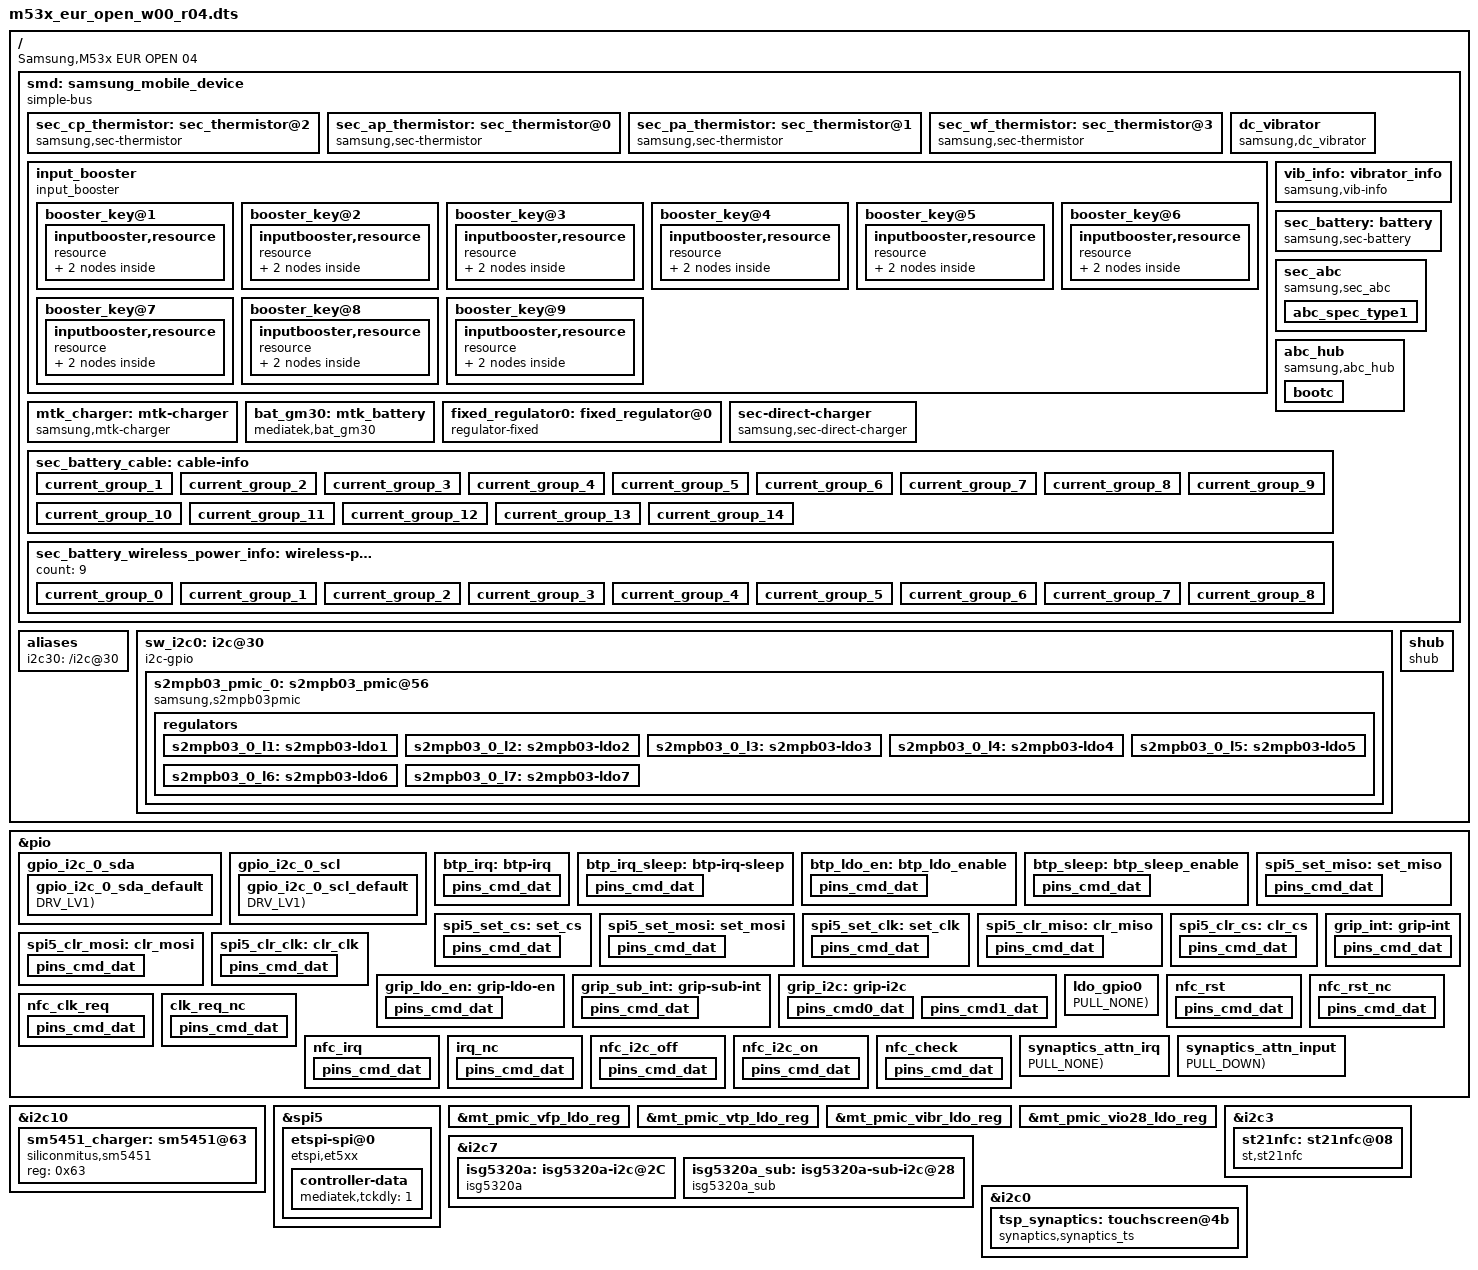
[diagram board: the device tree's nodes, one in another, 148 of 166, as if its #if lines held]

/*
 * Copyright (c) 2018 Samsung Electronics Co., Ltd.
 *              http://www.samsung.com
 *
 * This program is free software; you can redistribute it and/or modify
 * it under the terms of the GNU General Public License version 2 as
 * published by the Free Software Foundation.
*/

/dts-v1/;
/plugin/;
/ {
	fragment@smd {
		target-path = "/";
		__overlay__ {
			smd: samsung_mobile_device {
				compatible = "simple-bus";
			};
		};
	};
};

/* #include "../common/input_booster_mt6877.dtsi" */ /* From input_booster_mt6877.py */
/* Copyright (c) 2019, The Linux Foundation. All rights reserved.
 *
 * This program is free software; you can redistribute it and/or modify
 * it under the terms of the GNU General Public License version 2 and
 * only version 2 as published by the Free Software Foundation.
 *
 * This program is distributed in the hope that it will be useful,
 * but WITHOUT ANY WARRANTY; without even the implied warranty of
 * MERCHANTABILITY or FITNESS FOR A PARTICULAR PURPOSE.  See the
 * GNU General Public License for more details.
 */

&smd {
	input_booster {
		status = "okay";
		compatible = "input_booster";
		resValcount = "2";
		max_resource_count = "3";
		max_cluster_count = "3";
		#address-cells = <1>;
		#size-cells = <0>;

		/* Each Cpu Cluster Start Cpu */
		cpu_cluster_policy = "6,0";

		/* < CPU, DDR, SCHEDBOOST > */
		ib_release_values = "-1,16,0";

		/* Select Allowed Resource Index Group */
		allowed_resources = "0,1";

		booster_key@1 {
			input_booster,label = "key";
			input_booster,type = <0>;	/* BOOSTER_DEVICE_KEY */

			/* Time table */
			input_booster,head_time = <200>;
			input_booster,tail_time = <0>;

			/* Resource Table Sequentially identified with index
			 * CPU's ID & Index : 0
			 * DDR's ID & Index : 1
			*/

			/* Input Booster Resource Frequency */
			inputbooster,resource {
				compatible = "resource";
				resource@1 {
					resource,label = "CPU";
					resource,value = <1540000 0>;
				};

				resource@2 {
					resource,label = "DDR";
					resource,value = <0 0>;
				};
			};
		};

		booster_key@2 {
			input_booster,label = "touchkey";
			input_booster,type = <1>;	/* BOOSTER_DEVICE_TOUCHKEY */

			/* Time table */
			input_booster,head_time = <1>;
			input_booster,tail_time = <300>;

			/* Input Booster Resource Frequency */
			inputbooster,resource {
				compatible = "resource";
				resource@1 {
					resource,label = "CPU";
					resource,value = <0 1540000>;
				};

				resource@2 {
					resource,label = "DDR";
					resource,value = <0 0>;
				};
			};
		};

		booster_key@3 {
			input_booster,label = "touch";
			input_booster,type = <2>;	/* BOOSTER_DEVICE_TOUCH */

			/* Time table */
			input_booster,head_time = <130>;
			input_booster,tail_time = <500>;

			/* Input Booster Resource Frequency */
			inputbooster,resource {
				compatible = "resource";
				resource@1 {
					resource,label = "CPU";
					resource,value = <1140000 1075200>;
				};

				resource@2 {
					resource,label = "DDR";
					resource,value = <4266 4266>;
				};
			};
		};

		booster_key@4 {
			input_booster,label = "multitouch";
			input_booster,type = <3>;	/* BOOSTER_DEVICE_MULTITOUCH */

			/* Time table */
			input_booster,head_time = <1000>;
			input_booster,tail_time = <500>;

			/* Input Booster Resource Frequency */
			inputbooster,resource {
				compatible = "resource";
				resource@1 {
					resource,label = "CPU";
					resource,value = <1140000 1075200>;
				};

				resource@2 {
					resource,label = "DDR";
					resource,value = <4266 4266>;
				};
			};
		};

		booster_key@5 {
			input_booster,label = "keyboard";
			input_booster,type = <4>;	/* BOOSTER_DEVICE_KEYBOARD */

			/* Time table */
			input_booster,head_time = <130>;
			input_booster,tail_time = <130>;

			/* Input Booster Resource Frequency */
			inputbooster,resource {
				compatible = "resource";
				resource@1 {
					resource,label = "CPU";
					resource,value = <1430000 1040000>;
				};

				resource@2 {
					resource,label = "DDR";
					resource,value = <4266 4266>;
				};
			};
		};

		booster_key@6 {
			input_booster,label = "MOUSE";
			input_booster,type = <5>;	/* BOOSTER_DEVICE_MOUSE */

			/* Time table */
			input_booster,head_time = <200>;
			input_booster,tail_time = <300>;

			/* Input Booster Resource Frequency */
			inputbooster,resource {
				compatible = "resource";
				resource@1 {
					resource,label = "CPU";
					resource,value = <1430000 1040000>;
				};

				resource@2 {
					resource,label = "DDR";
					resource,value = <4266 4266>;
				};
			};
		};

		booster_key@7 {
			input_booster,label = "mouse_wheel";
			input_booster,type = <6>;	/* BOOSTER_DEVICE_MOUSE */

			/* Time table */
			input_booster,head_time = <200>;
			input_booster,tail_time = <0>;

			/* Input Booster Resource Frequency */
			inputbooster,resource {
				compatible = "resource";
				resource@1 {
					resource,label = "CPU";
					resource,value = <1430000 0>;
				};

				resource@2 {
					resource,label = "DDR";
					resource,value = <4266 0>;
				};
			};
		};

		booster_key@8 {
			input_booster,label = "pen_hover";
			input_booster,type = <7>;	/* BOOSTER_DEVICE_MOUSE */

			/* Time table */
			input_booster,head_time = <200>;
			input_booster,tail_time = <300>;

			/* Input Booster Resource Frequency */
			inputbooster,resource {
				compatible = "resource";
				resource@1 {
					resource,label = "CPU";
					resource,value = <1430000 1040000>;
				};

				resource@2 {
					resource,label = "DDR";
					resource,value = <0 0>;
				};
			};
		};

		booster_key@9 {
			input_booster,label = "pen";
			input_booster,type = <8>;	/* BOOSTER_DEVICE_MOUSE */

			/* Time table */
			input_booster,head_time = <200>;
			input_booster,tail_time = <600>;

			/* Input Booster Resource Frequency */
			inputbooster,resource {
				compatible = "resource";
				resource@1 {
					resource,label = "CPU";
					resource,value = <1800000 1040000>;
				};

				resource@2 {
					resource,label = "DDR";
					resource,value = <4266 4266>;
				};
			};
		};
		/* If you need to add new key type, add it this position */
	};
};

/* #include "../sec_pinctrl_wrapper.dtsi" */         /* From sec_pinctrl_wrapper.py */
#define PIN_FUNC_INPUT		input-enable
#define PIN_FUNC_INPUT_WAKEUP	input-enable
#define PIN_FUNC_OUTPUT		output-enable
#define PIN_FUNC_OUTPUT_HIGH		output-high
#define PIN_FUNC_OUTPUT_LOW		output-low

#define PIN_PULL_NONE	bias-disable
#define PIN_PULL_DOWN	bias-pull-down
#define PIN_PULL_UP	bias-pull-up
#define PIN_PULL_OPEN	bias-high-impedance

/*
 * MTK_DRIVE_2mA  2
 * MTK_DRIVE_4mA  4
 * MTK_DRIVE_6mA  6
 * MTK_DRIVE_8mA  8
 * MTK_DRIVE_10mA 10
 * MTK_DRIVE_12mA 12
 * MTK_DRIVE_14mA 14
 * MTK_DRIVE_16mA 16
 */

#define PIN_DRV_LV1	2
#define PIN_DRV_LV2	4
#define PIN_DRV_LV3	6
#define PIN_DRV_LV4	8
#define PIN_DRV_LV5	10
#define PIN_DRV_LV6	12
#define PIN_DRV_LV7	14
#define PIN_DRV_LV8	16

#define PIN_EXPAND(pin) #pin

#define SEC_GPIO(src, type, num)	PIN_EXPAND(gpio##num)
#define SEC_GPIO_REF(src, type, num)	&type num
#define SEC_GPIO_NUM(src, type, num)	num
#define SEC_GPIO_TYPE(src, type, num)	&type
#define SEC_GPIO_PHANDLE_ACTIVE(src, type, num)	SEC_GPIO_PHANDLE(type, num, active)
#define SEC_GPIO_PHANDLE_SLEEP(src, type, num)	SEC_GPIO_PHANDLE(type, num, sleep)
#define SEC_GPIO_PHANDLE(type, num, mode)	type##_##num##_##mode

#define MTK_PINMUX(gpio, func) (MTK_PIN_NO(gpio) | func)

#define GPIO_CONFIG(_src, _type, _num, _func)		\
	pins_cmd_dat{					\
		pinmux = <MTK_PINMUX(SEC_GPIO_NUM(_src, _type, _num), 0)>;	\
		PIN_ ##_func;		\
	}

#define GPIO_CONFIG_PUD(_src, _type, _num, _func, _pull)	\
	pins_cmd_dat{					\
		pinmux = <MTK_PINMUX(SEC_GPIO_NUM(_src, _type, _num), 0)>;	\
		PIN_ ##_pull;				\
		PIN_ ##_func;		\
	}

#define GPIO_CONFIG_PUD_DRV(_src, _type, _num, _func, _pull, _drv)	\
	pins_cmd_dat{					\
		pinmux = <MTK_PINMUX(SEC_GPIO_NUM(_src, _type, _num), 0)>;	\
		PIN_ ##_pull;				\
		PIN_ ##_func;		\
		drive-strength = <PIN_ ##_drv>;	\
	}

#define SEC_ADC(type, num) <&type num>
#define SEC_ADC_OPT(type, num) ,<&type num>
#define SEC_ADC_NUM(type, num) <num>

/* #include "../vibrator_vib_info.dtsi" */           /* From vibrator_vib_info.py */

&smd {
	vib_info: vibrator_info {
		status = "okay";
		compatible = "samsung,vib-info";
		functions = "";
#if 0
		samsung,intensities = <>;
#else
		samsung,intensities = <>;
#endif

#if 0
		samsung,haptic_intensities = <>;
#else
		samsung,haptic_intensities = <>;
#endif
	};
};

/* #include "../mtk_charger.dtsi" */                 /* From mtk_charger.py */

&smd {
	mtk_charger: mtk-charger {
		compatible = "samsung,mtk-charger";
#if defined(CONFIG_SEC_FACTORY)
		charger,vbus_min_charger_voltage = <4200000>;
		charger,vbus_normal_mivr_voltage = <4200000>;
#else
		charger,vbus_min_charger_voltage = <4400000>;
		charger,vbus_normal_mivr_voltage = <4400000>;
#endif
		charger,gpio_ilim = <&pio 140 0x0>;
		charger,gpio_chgenb = <&pio 135 0x0>;
		charger,max_icl = <3250>;
		charger,ib_fcc = <100>;
	};

	battery {
		battery,otg_name = "mtk-otg";
	};
};

/* /home/dpi/qb5_8814/workspace/P4_1716/android/kernel/kmodule/battery/suwon/charger/mtk_charger/mtk_charger.m53x.dtsi */

&smd {
	mtk_charger: mtk-charger {
		charger,vbus_min_charger_voltage = <4400000>;
		charger,vbus_normal_mivr_voltage = <4400000>;
		charger,gpio_ilim = <&pio 111 0x0>;
		charger,gpio_chgenb = <&pio 142 0x0>;
	};
};

/* #include "../mtk_fuelgauge.dtsi" */               /* From mtk_fuelgauge.py */
&smd {
	battery {
		battery,fuelgauge_name = "mtk-fg-battery";
	};

	/* battery_prop.dtsi */
	bat_gm30: mtk_battery{
		compatible = "mediatek,bat_gm30";
		DIFFERENCE_FULLOCV_ITH = <(300)>;
	/*	Charging termination current*/
		SHUTDOWN_1_TIME = <(60)>;
	/*	If ui_soc shows 1% more than X minites, system will shutdown*/
		KEEP_100_PERCENT = <(1)>;
	/*	The ui_soc will keep 100% until SOC drop X percents after unplugged */
		R_FG_VALUE = <(5)>;
	/*	R_sense resistance*/
		EMBEDDED_SEL = <(0)>;
	/*	Configures whether using embedded battery or not*/
		PMIC_SHUTDOWN_CURRENT = <(20)>;
	/*	System shutdown current*/
		FG_METER_RESISTANCE = <(100)>;
	/*	The resistance of PCB*/
		CAR_TUNE_VALUE = <(99)>;
	/*	Tune value for current measurement*/
		PMIC_MIN_VOL = <(33500)>;
	/*	vboot voltage for gauge 0%*/
		POWERON_SYSTEM_IBOOT = <(500)>;
	/*	power on system iboot*/
		SHUTDOWN_GAUGE0 = <(0)>;
	/*	Shutdown condition2 switch*/
		SHUTDOWN_GAUGE0_VOLTAGE = <(34000)>;
	/*	shutdown gauge 0% voltage*/
		TEMPERATURE_T0 = <(50)>;
	/*	Battery temperature T0*/
		TEMPERATURE_T1 = <(25)>;
	/*	Battery temperature T1*/
		TEMPERATURE_T2 = <(10)>;
	/*	Battery temperature T2*/
		TEMPERATURE_T3 = <(0)>;
	/*	Battery temperature T3*/
		TEMPERATURE_T4 = <(-10)>;
	/*	Battery temperature T4*/
		TEMPERATURE_T5 = <(-20)>;
	/*	Battery temperature T5*/
		g_FG_PSEUDO100_T0 = <(93)>;
	/*	Pseudo 100% percentage at T0*/
		g_FG_PSEUDO100_T1 = <(93)>;
	/*	Pseudo 100% percentage at T1*/
		g_FG_PSEUDO100_T2 = <(93)>;
	/*	Pseudo 100% percentage at T2*/
		g_FG_PSEUDO100_T3 = <(93)>;
	/*	Pseudo 100% percentage at T3*/
		g_FG_PSEUDO100_T4 = <(93)>;
	/*	Pseudo 100% percentage at T4*/
		g_FG_PSEUDO100_T5 = <(93)>;
	/*	Pseudo 100% percentage at T4*/
		Q_MAX_SYS_VOLTAGE_BAT0 = <(3350)>;
	/*	Pseudo1 for hide percentage*/
		Q_MAX_SYS_VOLTAGE_BAT1 = <(3350)>;
	/*	Pseudo1 for hide percentage*/
		Q_MAX_SYS_VOLTAGE_BAT2 = <(3350)>;
	/*	Pseudo1 for hide percentage*/
		Q_MAX_SYS_VOLTAGE_BAT3 = <(3350)>;
	/*	Pseudo1 for hide percentage*/
		COM_FG_METER_RESISTANCE = <(100)>;
	/*	compensate The resistance of PCB*/
		COM_R_FG_VALUE = <(0)>;
	/*	compensate R_sense resistance*/
		enable_tmp_intr_suspend = <(0)>;
	/* Enable update temp when suspend */
		ACTIVE_TABLE = <(6)>;
	/* Table numbers per battery*/
		MULTI_TEMP_GAUGE0 = <(1)>;
	/* Multi gauge0 enable*/
		HWOCV_OLDOCV_DIFF = <(100)>;
	/* Diff of HWOCV and SWOCV*/

	/* battery_table.dtsi*/
	battery0_profile_t0_num = <100>;
	battery0_profile_t0_col = <3>;
	battery0_profile_t0 =
	<
	0       43520   850
	486     43380   866
	972     43251   875
	1458    43130   897
	1944    43004   875
	2430    42881   875
	2916    42760   875
	3402    42644   875
	3888    42530   900
	4375    42407   875
	4861    42293   881
	5347    42178   900
	5833    42054   875
	6319    41941   897
	6805    41820   875
	7291    41714   875
	7777    41601   900
	8263    41485   875
	8749    41372   875
	9235    41267   897
	9721    41155   875
	10207   41051   875
	10693   40945   875
	11179   40837   884
	11665   40739   875
	12152   40642   900
	12638   40542   894
	13124   40446   919
	13610   40350   900
	14096   40253   900
	14582   40162   919
	15068   40070   925
	15554   39979   925
	16040   39898   941
	16526   39817   950
	17012   39736   950
	17498   39655   962
	17984   39573   975
	18470   39492   975
	18956   39411   1000
	19442   39329   1025
	19928   39210   975
	20415   39078   938
	20901   38949   878
	21387   38849   875
	21873   38773   850
	22359   38699   850
	22845   38635   850
	23331   38580   850
	23817   38521   850
	24303   38472   850
	24789   38423   850
	25275   38374   875
	25761   38326   850
	26247   38285   869
	26733   38239   850
	27219   38200   875
	27705   38157   866
	28192   38115   868
	28678   38082   872
	29164   38050   875
	29650   38007   853
	30136   37975   875
	30622   37952   900
	31108   37919   900
	31594   37887   900
	32080   37865   907
	32566   37841   925
	33052   37810   925
	33538   37765   900
	34024   37684   861
	34510   37614   865
	34996   37550   851
	35482   37511   859
	35968   37465   857
	36455   37424   853
	36941   37374   850
	37427   37337   875
	37913   37304   875
	38399   37272   875
	38885   37230   875
	39371   37185   900
	39857   37120   875
	40343   37063   875
	40829   37004   888
	41315   36942   879
	41801   36861   881
	42287   36806   860
	42773   36790   875
	43259   36780   891
	43745   36767   907
	44232   36751   948
	44718   36719   976
	45204   36643   1018
	45690   36372   937
	46176   35944   969
	46662   35387   1000
	47148   34581   1041
	47634   33318   1181
	48120   30130   10325
	>;
	battery0_profile_t1_num = <100>;
	battery0_profile_t1_col = <3>;
	battery0_profile_t1 =
	<
	0       43320   1450
	486     43164   1450
	972     43033   1475
	1458    42911   1475
	1944    42789   1475
	2430    42671   1475
	2916    42550   1456
	3402    42434   1475
	3888    42320   1475
	4375    42197   1440
	4861    42083   1431
	5347    41968   1428
	5833    41854   1437
	6319    41741   1428
	6805    41628   1431
	7291    41514   1425
	7777    41401   1425
	8263    41295   1425
	8749    41184   1407
	9235    41078   1403
	9721    40975   1412
	10207   40871   1425
	10693   40765   1425
	11179   40667   1416
	11665   40569   1425
	12152   40475   1450
	12638   40382   1450
	13124   40277   1450
	13610   40190   1450
	14096   40093   1447
	14582   40002   1444
	15068   39920   1460
	15554   39839   1450
	16040   39758   1450
	16526   39687   1500
	17012   39606   1500
	17498   39525   1500
	17984   39443   1504
	18470   39354   1525
	18956   39243   1490
	19442   39109   1425
	19928   38980   1344
	20415   38875   1319
	20901   38787   1300
	21387   38719   1313
	21873   38654   1300
	22359   38589   1300
	22845   38535   1290
	23331   38480   1300
	23817   38431   1291
	24303   38384   1300
	24789   38343   1300
	25275   38294   1300
	25761   38257   1303
	26247   38217   1325
	26733   38182   1309
	27219   38140   1325
	27705   38107   1341
	28192   38075   1332
	28678   38042   1350
	29164   38010   1350
	29650   37987   1375
	30136   37955   1375
	30622   37926   1375
	31108   37900   1376
	31594   37877   1384
	32080   37855   1400
	32566   37822   1378
	33052   37790   1375
	33538   37747   1375
	34024   37707   1356
	34510   37672   1360
	34996   37630   1351
	35482   37591   1359
	35968   37552   1350
	36455   37512   1372
	36941   37480   1375
	37427   37447   1375
	37913   37414   1394
	38399   37368   1385
	38885   37310   1376
	39371   37248   1393
	39857   37192   1400
	40343   37134   1423
	40829   37063   1412
	41315   36975   1425
	41801   36935   1425
	42287   36920   1460
	42773   36910   1475
	43259   36894   1500
	43745   36867   1514
	44232   36833   1573
	44718   36727   1613
	45204   36421   1607
	45690   35937   1688
	46176   35299   1804
	46662   34415   1951
	47148   32710   2488
	47634   30570   11550
	48120   30570   11550
	>;
	battery0_profile_t2_num = <100>;
	battery0_profile_t2_col = <3>;
	battery0_profile_t2 =
	<
	0       43000   3200
	486     42808   3293
	972     42661   3412
	1458    42531   3472
	1944    42404   3476
	2430    42281   3478
	2916    42160   3481
	3402    42044   3484
	3888    41930   3475
	4375    41817   3485
	4861    41695   3456
	5347    41579   3431
	5833    41474   3450
	6319    41361   3425
	6805    41255   3425
	7291    41144   3425
	7777    41041   3425
	8263    40931   3416
	8749    40834   3407
	9235    40737   3425
	9721    40640   3425
	10207   40541   3444
	10693   40435   3419
	11179   40337   3425
	11665   40229   3375
	12152   40138   3391
	12638   40047   3381
	13124   39957   3378
	13610   39875   3400
	14096   39794   3375
	14582   39712   3375
	15068   39640   3415
	15554   39559   3425
	16040   39472   3409
	16526   39382   3425
	17012   39269   3381
	17498   39146   3350
	17984   39008   3268
	18470   38894   3225
	18956   38801   3200
	19442   38720   3200
	19928   38655   3200
	20415   38590   3200
	20901   38534   3222
	21387   38479   3225
	21873   38426   3250
	22359   38377   3250
	22845   38329   3275
	23331   38280   3275
	23817   38241   3300
	24303   38202   3325
	24789   38162   3347
	25275   38130   3363
	25761   38087   3378
	26247   38055   3400
	26733   38022   3425
	27219   37990   3425
	27705   37967   3466
	28192   37935   3500
	28678   37911   3500
	29164   37885   3525
	29650   37859   3528
	30136   37842   3569
	30622   37822   3600
	31108   37800   3601
	31594   37784   3641
	32080   37757   3657
	32566   37732   3697
	33052   37700   3700
	33538   37667   3728
	34024   37627   3750
	34510   37592   3795
	34996   37559   3850
	35482   37517   3866
	35968   37482   3932
	36455   37434   3972
	36941   37374   4026
	37427   37314   4104
	37913   37249   4144
	38399   37190   4235
	38885   37119   4325
	39371   37028   4398
	39857   36965   4501
	40343   36932   4666
	40829   36905   4816
	41315   36877   5048
	41801   36845   5310
	42287   36790   5653
	42773   36689   6028
	43259   36466   6433
	43745   36033   6914
	44232   35419   7720
	44718   34544   8974
	45204   33115   11297
	45690   30950   12525
	46176   30950   12525
	46662   30950   12525
	47148   30950   12525
	47634   30950   12525
	48120   30950   12525
	>;
	battery0_profile_t3_num = <100>;
	battery0_profile_t3_col = <3>;
	battery0_profile_t3 =
	<
	0       42520   5950
	486     42262   6183
	972     42098   6518
	1458    41961   6640
	1944    41824   6714
	2430    41701   6753
	2916    41580   6775
	3402    41464   6816
	3888    41350   6825
	4375    41237   6840
	4861    41123   6825
	5347    41017   6847
	5833    40909   6825
	6319    40812   6847
	6805    40715   6844
	7291    40604   6825
	7777    40501   6825
	8263    40385   6784
	8749    40274   6782
	9235    40177   6800
	9721    40080   6800
	10207   39984   6778
	10693   39903   6781
	11179   39821   6784
	11665   39739   6800
	12152   39658   6791
	12638   39587   6825
	13124   39497   6803
	13610   39410   6813
	14096   39312   6797
	14582   39196   6756
	15068   39069   6680
	15554   38949   6625
	16040   38836   6584
	16526   38747   6569
	17012   38666   6550
	17498   38600   6575
	17984   38536   6579
	18470   38479   6600
	18956   38418   6635
	19442   38370   6675
	19928   38321   6691
	20415   38275   6706
	20901   38234   6725
	21387   38194   6750
	21873   38156   6775
	22359   38115   6794
	22845   38082   6835
	23331   38050   6850
	23817   38018   6891
	24303   37984   6907
	24789   37952   6925
	25275   37930   6975
	25761   37909   7003
	26247   37892   7044
	26733   37876   7084
	27219   37860   7125
	27705   37843   7183
	28192   37827   7214
	28678   37811   7295
	29164   37795   7351
	29650   37777   7407
	30136   37752   7488
	30622   37722   7544
	31108   37689   7626
	31594   37657   7723
	32080   37622   7813
	32566   37582   7939
	33052   37540   8076
	33538   37495   8238
	34024   37437   8422
	34510   37374   8610
	34996   37309   8853
	35482   37238   9080
	35968   37170   9352
	36455   37096   9676
	36941   37004   10017
	37427   36935   10393
	37913   36894   10858
	38399   36862   11389
	38885   36830   11982
	39371   36791   12670
	39857   36740   13453
	40343   36656   14301
	40829   36424   15025
	41315   35986   15823
	41801   35349   16953
	42287   34442   18475
	42773   33430   18575
	43259   33430   18575
	43745   33430   18575
	44232   33430   18575
	44718   33430   18575
	45204   33430   18575
	45690   33430   18575
	46176   33430   18575
	46662   33430   18575
	47148   33430   18575
	47634   33430   18575
	48120   33430   18575
	>;
	battery0_profile_t4_num = <100>;
	battery0_profile_t4_col = <3>;
	battery0_profile_t4 =
	<
	0       42010   11330
	486     41738   11604
	972     41429   12066
	1458    41171   12469
	1944    40989   12751
	2430    40838   12878
	2916    40700   12919
	3402    40570   12916
	3888    40440   12875
	4375    40311   12819
	4861    40181   12744
	5347    40058   12703
	5833    39949   12675
	6319    39842   12650
	6805    39745   12650
	7291    39648   12616
	7777    39541   12526
	8263    39441   12509
	8749    39332   12437
	9235    39227   12378
	9721    39115   12312
	10207   39013   12272
	10693   38923   12250
	11179   38841   12216
	11665   38759   12200
	12152   38694   12184
	12638   38622   12175
	13124   38565   12175
	13610   38510   12200
	14096   38456   12178
	14582   38407   12200
	15068   38358   12210
	15554   38310   12225
	16040   38261   12241
	16526   38215   12256
	17012   38174   12297
	17498   38140   12325
	17984   38097   12329
	18470   38065   12350
	18956   38032   12375
	19442   38010   12450
	19928   37977   12475
	20415   37955   12506
	20901   37931   12568
	21387   37905   12626
	21873   37874   12675
	22359   37855   12770
	22845   37832   12819
	23331   37800   12900
	23817   37778   13031
	24303   37744   13121
	24789   37712   13242
	25275   37670   13327
	25761   37626   13460
	26247   37577   13639
	26733   37535   13728
	27219   37480   13875
	27705   37420   14031
	28192   37359   14202
	28678   37294   14386
	29164   37230   14552
	29650   37155   14720
	30136   37090   14944
	30622   37028   15148
	31108   36979   15354
	31594   36947   15613
	32080   36905   15847
	32566   36863   16130
	33052   36790   16376
	33538   36673   16644
	34024   36429   16891
	34510   36018   17215
	34996   35399   17761
	35482   34431   18699
	35968   32802   17069
	36455   31080   12750
	36941   31080   12750
	37427   31080   12750
	37913   31080   12750
	38399   31080   12750
	38885   31080   12750
	39371   31080   12750
	39857   31080   12750
	40343   31080   12750
	40829   31080   12750
	41315   31080   12750
	41801   31080   12750
	42287   31080   12750
	42773   31080   12750
	43259   31080   12750
	43745   31080   12750
	44232   31080   12750
	44718   31080   12750
	45204   31080   12750
	45690   31080   12750
	46176   31080   12750
	46662   31080   12750
	47148   31080   12750
	47634   31080   12750
	48120   31080   12750
	>;
	battery0_profile_t5_num = <100>;
	battery0_profile_t5_col = <3>;
	battery0_profile_t5 =
	<
	0       40920   10780
	483     40610   11233
	967     40337   12231
	1450    40095   12975
	1933    39872   13686
	2417    39674   14479
	2900    39510   15208
	3383    39378   15667
	3867    39258   15931
	4350    39150   16075
	4833    39042   16178
	5317    38929   16164
	5800    38830   16208
	6283    38733   16319
	6767    38652   16378
	7250    38573   16404
	7733    38509   16464
	8217    38444   16519
	8700    38390   16625
	9183    38335   16666
	9667    38292   16706
	10150   38244   16725
	10633   38200   16750
	11117   38158   16752
	11600   38126   16810
	12083   38087   16833
	12567   38052   16965
	13050   38019   16990
	13533   37987   17100
	14017   37955   17176
	14500   37919   17218
	14983   37880   17323
	15467   37838   17390
	15950   37794   17510
	16433   37738   17550
	16917   37683   17714
	17400   37629   17828
	17883   37564   17981
	18367   37500   18070
	18850   37427   18222
	19333   37361   18385
	19817   37286   18407
	20300   37222   18563
	20783   37158   18764
	21267   37093   18919
	21750   37039   19080
	22233   36974   19247
	22717   36910   19451
	23200   36824   19655
	23683   36692   19921
	24167   36470   20134
	24650   36118   20420
	25133   35546   20803
	25617   34662   21167
	26100   33270   18200
	26583   32530   16450
	27067   32530   16450
	27550   32530   16450
	28033   32530   16450
	28517   32530   16450
	29000   32530   16450
	29483   32530   16450
	29967   32530   16450
	30450   32530   16450
	30933   32530   16450
	31417   32530   16450
	31900   32530   16450
	32383   32530   16450
	32867   32530   16450
	33350   32530   16450
	33833   32530   16450
	34317   32530   16450
	34800   32530   16450
	35283   32530   16450
	35767   32530   16450
	36250   32530   16450
	36733   32530   16450
	37217   32530   16450
	37700   32530   16450
	38183   32530   16450
	38667   32530   16450
	39150   32530   16450
	39633   32530   16450
	40117   32530   16450
	40600   32530   16450
	41083   32530   16450
	41567   32530   16450
	42050   32530   16450
	42533   32530   16450
	43017   32530   16450
	43500   32530   16450
	43983   32530   16450
	44467   32530   16450
	44950   32530   16450
	45433   32530   16450
	45917   32530   16450
	46400   32530   16450
	46883   32530   16450
	47367   32530   16450
	47850   32530   16450
	>;

	/* battery_prop_dim2_ext.dtsi */
	/*vboot voltage for gauge 0%*/
	g_PMIC_MIN_VOL_row = <4>;
	g_PMIC_MIN_VOL_col = <10>;
	g_PMIC_MIN_VOL =
	<
		32700  32700  32700  32700
		32700  32700  32700  32700
		32700  32700  32700  32700
		32200  32200  32200  32200
		31000  31000  31000  31000
		31500  31500  31500  31500
		31000  31000  31000  31000
		31000  31000  31000  31000
		31000  31000  31000  31000
		31000  31000  31000  31200
	>;
	/*boot_up current for gauge 0%*/
	g_PON_SYS_IBOOT_row = <4>;
	g_PON_SYS_IBOOT_col = <10>;
	g_PON_SYS_IBOOT =
	<
		5000  5000  5000  5000
		5000  5000  5000  5000
		5000  5000  5000  5000
		5000  5000  5000  5000
		5000  5000  5000  5000
		5000  5000  5000  5000
		5000  5000  5000  5000
		5000  5000  5000  5000
		5000  5000  5000  5000
		5000  5000  5000  5000
	>;
	/*Pseudo1 hide percentage*/
	g_QMAX_SYS_VOL_row = <4>;
	g_QMAX_SYS_VOL_col = <10>;
	g_QMAX_SYS_VOL =
	<
		33600  33600  33600  33600
		33600  33600  33600  33600
		33600  33600  33600  33600
		33600  33600  33600  33600
		33600  33600  33600  33600
		32500  32500  32500  32500
		32800  32800  32800  32800
		32800  32800  32800  32800
		32800  32800  32800  32800
		32800  32800  32800  32800
	>;
	/*Pseudo100 percentage setting*/
	g_FG_PSEUDO100_row = <4>;
	g_FG_PSEUDO100_col = <10>;
	g_FG_PSEUDO100 =
	<
		91  100  100  100
		91  100  100  100
		91  100  100  100
		91  100  100  100
		91  100  100  100
		91  100  100  100
		100  100  100  100
		100  100  100  100
		100  100  100  100
		100  100  100  100
	>;

	};
};

/* /home/dpi/qb5_8814/workspace/P4_1716/android/kernel/kmodule/battery/suwon/fuelgauge/mtk_fuelgauge/mtk_fuelgauge.m53x.dtsi */
&smd {
	battery {
		battery,fuelgauge_name = "mtk-fg-battery";
	};

	/* battery_prop.dtsi */
bat_gm30: mtk_battery{
	compatible = "mediatek,bat_gm30";

	RBAT_TYPE = <(100)>;
	RBAT_PULL_UP_R = <(100000)>;

	rbat_temperature_table_num = <21>;
	rbat_battery_temperature =
	<
		(-40) 4397119
		(-35) 3088598
		(-30) 2197225
		(-25) 1581880
		(-20) 1151036
		(-15) 846578
		(-10) 628988
		(-5) 471632
		0 357011
		5 272499
		10 209709
		15 162650
		20 127080
		25 100000
		30 79221
		35 63167
		40 50676
		45 40903
		50 33194
		55 27090
		60 22224 >;
/* battery temperature table type - NTC table */
	BatteryID_GPIO_1 = <&pio 21 0>;
	BatteryID_GPIO = <&pio 22 0>;
/* Battery ID distinction */
	DIFFERENCE_FULLOCV_ITH = <(300)>; /* M53 : 250mA +50mA */
/*	Charging termination current*/
	SHUTDOWN_1_TIME = <(60)>;
/*	If ui_soc shows 1% more than X minites, system will shutdown*/
	KEEP_100_PERCENT = <(1)>;
/*	The ui_soc will keep 100% until SOC drop X percents after unplugged*/
	R_FG_VALUE = <(5)>;
/*	R_sense resistance*/
	EMBEDDED_SEL = <(0)>;
/*	Configures whether using embedded battery or not*/
	PMIC_SHUTDOWN_CURRENT = <(20)>;
/*	System shutdown current*/
	FG_METER_RESISTANCE = <(100)>;
/*	The resistance of PCB*/
	CAR_TUNE_VALUE = <(100)>;
/*	Tune value for current measurement*/
	PMIC_MIN_VOL = <(33500)>;
/*	vboot voltage for gauge 0%*/
	POWERON_SYSTEM_IBOOT = <(500)>;
/*	power on system iboot*/
	SHUTDOWN_GAUGE0 = <(0)>;
/*	Shutdown condition2 switch*/
	SHUTDOWN_GAUGE0_VOLTAGE = <(34000)>;
/*	shutdown gauge 0% voltage*/
	TEMPERATURE_T0 = <(50)>;
/*	Battery temperature T0*/
	TEMPERATURE_T1 = <(25)>;
/*	Battery temperature T1*/
	TEMPERATURE_T2 = <(10)>;
/*	Battery temperature T2*/
	TEMPERATURE_T3 = <(0)>;
/*	Battery temperature T3*/
	TEMPERATURE_T4 = <(-10)>;
/*	Battery temperature T4*/
	TEMPERATURE_T5 = <(-20)>;
/*	Battery temperature T5*/
	g_FG_PSEUDO100_T0 = <(100)>;
/*	Pseudo 100% percentage at T0*/
	g_FG_PSEUDO100_T1 = <(100)>;
/*	Pseudo 100% percentage at T1*/
	g_FG_PSEUDO100_T2 = <(100)>;
/*	Pseudo 100% percentage at T2*/
	g_FG_PSEUDO100_T3 = <(100)>;
/*	Pseudo 100% percentage at T3*/
	g_FG_PSEUDO100_T4 = <(100)>;
/*	Pseudo 100% percentage at T4*/
	g_FG_PSEUDO100_T5 = <(100)>;
/*	Pseudo 100% percentage at T4*/
	Q_MAX_SYS_VOLTAGE_BAT0 = <(3350)>;
/*	Pseudo1 for hide percentage*/
	Q_MAX_SYS_VOLTAGE_BAT1 = <(3350)>;
/*	Pseudo1 for hide percentage*/
	Q_MAX_SYS_VOLTAGE_BAT2 = <(3350)>;
/*	Pseudo1 for hide percentage*/
	Q_MAX_SYS_VOLTAGE_BAT3 = <(3350)>;
/*	Pseudo1 for hide percentage*/
	COM_FG_METER_RESISTANCE = <(100)>;
/*	compensate The resistance of PCB*/
	COM_R_FG_VALUE = <(0)>;
/*	compensate R_sense resistance*/
	enable_tmp_intr_suspend = <(0)>;
/* Enable update temp when suspend */
	ACTIVE_TABLE = <(6)>;
/* Table numbers per battery*/
	MULTI_TEMP_GAUGE0 = <(1)>;
/* Multi gauge0 enable*/
	HWOCV_OLDOCV_DIFF = <(100)>;
/* Diff of HWOCV and SWOCV*/
	UI_FULL_LIMIT_EN = <(1)>;
	UI_FULL_LIMIT_SOC0 = <(9545)>;
	UI_FULL_LIMIT_ITH0 = <(14000)>;
	UI_FULL_LIMIT_SOC1 = <(9645)>;
	UI_FULL_LIMIT_ITH1 = <(12500)>;
	UI_FULL_LIMIT_SOC2 = <(9745)>;
	UI_FULL_LIMIT_ITH2 = <(11000)>;
	UI_FULL_LIMIT_SOC3 = <(9845)>;
	UI_FULL_LIMIT_ITH3 = <(9500)>;
	UI_FULL_LIMIT_SOC4 = <(9945)>;
	UI_FULL_LIMIT_ITH4 = <(7700)>;
/* Using current to limit uisoc in 100% case*/
	DYNAMIC_CV_FACTOR = <(100)>;
/* Dynamic CV offset */
	CHARGER_IEOC = <(250)>;
/* Charger termination current for Dynamic CV */

/* battery_table.dtsi*/
battery0_profile_t0_num = <100>;
battery0_profile_t0_col = <3>;
battery0_profile_t0 =
<
0       43990   475
474     43854   475
948     43739   500
1423    43628   500
1897    43515   500
2371    43404   500
2845    43289   488
3320    43182   500
3794    43062   500
4268    42949   500
4742    42831   500
5217    42708   498
5691    42587   501
6165    42471   510
6639    42354   525
7114    42228   506
7588    42111   516
8062    41992   524
8536    41876   525
9011    41751   503
9485    41640   525
9959    41529   532
10433   41419   550
10908   41298   525
11382   41185   525
11856   41081   541
12330   40974   550
12805   40863   530
13279   40762   565
13753   40652   526
14227   40551   550
14702   40450   550
15176   40355   569
15650   40260   575
16124   40165   575
16598   40070   575
17073   39985   600
17547   39897   616
18021   39806   607
18495   39719   625
18970   39628   625
19444   39529   625
19918   39397   585
20392   39246   525
20867   39127   506
21341   39032   509
21815   38952   501
22289   38879   500
22764   38816   500
23238   38752   500
23712   38689   500
24186   38633   500
24661   38576   500
25135   38519   500
25609   38471   500
26083   38424   525
26558   38376   525
27032   38329   525
27506   38280   525
27980   38239   514
28455   38197   525
28929   38158   525
29403   38121   525
29877   38082   547
30352   38051   550
30826   38018   552
31300   37980   558
31774   37945   550
32248   37913   550
32723   37874   555
33197   37810   500
33671   37731   514
34145   37654   505
34620   37599   506
35094   37550   500
35568   37511   523
36042   37455   500
36517   37417   525
36991   37369   508
37465   37334   525
37939   37294   503
38414   37257   525
38888   37199   524
39362   37136   500
39836   37074   505
40311   37018   505
40785   36951   510
41259   36872   525
41733   36825   489
42208   36819   522
42682   36803   500
43156   36797   525
43630   36772   525
44105   36746   550
44579   36662   550
45053   36398   566
45527   36003   625
46002   35496   665
46476   34819   735
46950   33830   850
>;
battery0_profile_t1_num = <100>;
battery0_profile_t1_col = <3>;
battery0_profile_t1 =
<
0       43900   750
474     43774   750
948     43669   800
1423    43558   781
1897    43449   784
2371    43344   800
2845    43234   800
3320    43122   800
3794    43002   800
4268    42889   800
4742    42771   800
5217    42648   800
5691    42527   801
6165    42411   810
6639    42286   800
7114    42168   800
7588    42051   800
8062    41932   800
8536    41811   800
9011    41701   803
9485    41583   807
9959    41469   807
10433   41359   825
10908   41248   825
11382   41135   825
11856   41031   841
12330   40924   850
12805   40813   850
13279   40712   850
13753   40611   874
14227   40511   875
14702   40410   879
15176   40307   881
15650   40210   883
16124   40115   900
16598   40030   925
17073   39935   925
17547   39847   925
18021   39754   925
18495   39667   946
18970   39564   925
19444   39459   924
19918   39317   845
20392   39186   796
20867   39075   775
21341   38982   741
21815   38912   749
22289   38839   738
22764   38776   750
23238   38712   733
23712   38659   743
24186   38603   747
24661   38546   725
25135   38499   750
25609   38451   750
26083   38404   750
26558   38356   750
27032   38319   750
27506   38270   750
27980   38233   750
28455   38196   771
28929   38155   750
29403   38124   775
29877   38092   797
30352   38061   787
30826   38028   798
31300   37997   792
31774   37965   800
32248   37933   779
32723   37902   800
33197   37860   775
33671   37817   761
34145   37766   750
34620   37727   750
35094   37690   750
35568   37642   727
36042   37595   725
36517   37558   727
36991   37519   733
37465   37484   750
37939   37453   750
38414   37407   750
38888   37349   750
39362   37286   750
39836   37234   755
40311   37178   775
40785   37101   750
41259   37022   774
41733   36975   764
42208   36960   775
42682   36953   775
43156   36937   782
43630   36921   822
44105   36886   825
44579   36822   873
45053   36575   866
45527   36160   911
46002   35630   990
46476   34925   1123
46950   33930   1425
>;
battery0_profile_t2_num = <100>;
battery0_profile_t2_col = <3>;
battery0_profile_t2 =
<
0       43620   1525
474     43458   1554
948     43337   1625
1423    43218   1644
1897    43095   1659
2371    42975   1675
2845    42859   1675
3320    42742   1675
3794    42622   1692
4268    42499   1675
4742    42381   1696
5217    42259   1686
5691    42137   1675
6165    42017   1675
6639    41904   1695
7114    41785   1675
7588    41671   1691
8062    41554   1699
8536    41442   1700
9011    41331   1725
9485    41220   1707
9959    41109   1725
10433   40999   1725
10908   40892   1725
11382   40788   1726
11856   40685   1750
12330   40584   1775
12805   40481   1775
13279   40376   1785
13753   40281   1800
14227   40177   1800
14702   40082   1800
15176   39985   1819
15650   39890   1825
16124   39786   1802
16598   39685   1813
17073   39563   1771
17547   39421   1709
18021   39290   1644
18495   39170   1604
18970   39074   1589
19444   38989   1550
19918   38920   1560
20392   38851   1571
20867   38780   1550
21341   38720   1559
21815   38662   1551
22289   38609   1575
22764   38557   1578
23238   38502   1583
23712   38452   1575
24186   38404   1596
24661   38356   1600
25135   38319   1625
25609   38271   1609
26083   38234   1625
26558   38186   1625
27032   38153   1650
27506   38121   1650
27980   38079   1650
28455   38047   1675
28929   38015   1675
29403   37984   1675
29877   37952   1697
30352   37921   1700
30826   37889   1676
31300   37857   1700
31774   37825   1700
32248   37793   1700
32723   37752   1685
33197   37710   1675
33671   37673   1700
34145   37627   1704
34620   37595   1725
35094   37554   1725
35568   37522   1747
36042   37476   1787
36517   37418   1800
36991   37353   1817
37465   37292   1831
37939   37245   1871
38414   37174   1885
38888   37090   1900
39362   37023   1925
39836   36998   1958
40311   36983   2018
40785   36957   2041
41259   36941   2097
41733   36916   2162
42208   36866   2256
42682   36714   2366
43156   36354   2472
43630   35840   2650
44105   35152   2943
44579   34223   3399
45053   33330   3975
45527   33330   3975
46002   33330   3975
46476   33330   3975
46950   33330   3975
>;
battery0_profile_t3_num = <100>;
battery0_profile_t3_col = <3>;
battery0_profile_t3 =
<
0       43160   3150
474     42932   3252
948     42785   3379
1423    42651   3456
1897    42521   3525
2371    42395   3548
2845    42269   3563
3320    42152   3600
3794    42026   3600
4268    41909   3625
4742    41791   3646
5217    41668   3650
5691    41547   3651
6165    41437   3675
6639    41326   3655
7114    41215   3675
7588    41105   3716
8062    40992   3700
8536    40881   3714
9011    40781   3722
9485    40670   3754
9959    40569   3825
10433   40459   3781
10908   40358   3789
11382   40256   3825
11856   40154   3825
12330   40056   3825
12805   39961   3845
13279   39862   3840
13753   39761   3825
14227   39661   3850
14702   39546   3821
15176   39420   3781
15650   39283   3717
16124   39157   3654
16598   39050   3638
17073   38956   3625
17547   38877   3641
18021   38806   3675
18495   38736   3675
18970   38673   3700
19444   38610   3700
19918   38556   3740
20392   38495   3754
20867   38447   3775
21341   38399   3825
21815   38351   3849
22289   38299   3877
22764   38257   3903
23238   38209   3925
23712   38172   3957
24186   38123   3997
24661   38091   4037
25135   38059   4075
25609   38017   4107
26083   37986   4130
26558   37954   4170
27032   37923   4209
27506   37890   4225
27980   37869   4264
28455   37849   4307
28929   37825   4350
29403   37804   4408
29877   37772   4447
30352   37751   4537
30826   37718   4604
31300   37687   4700
31774   37645   4762
32248   37605   4841
32723   37562   4956
33197   37510   5049
33671   37467   5193
34145   37404   5318
34620   37349   5477
35094   37283   5626
35568   37213   5791
36042   37140   5964
36517   37056   6138
36991   36992   6379
37465   36941   6643
37939   36903   6923
38414   36871   7261
38888   36839   7683
39362   36792   8218
39836   36715   8889
40311   36555   9692
40785   36264   10658
41259   35821   11990
41733   35195   14328
42208   34350   17484
42682   33770   19475
43156   33770   19475
43630   33770   19475
44105   33770   19475
44579   33770   19475
45053   33770   19475
45527   33770   19475
46002   33770   19475
46476   33770   19475
46950   33770   19475
>;
battery0_profile_t4_num = <100>;
battery0_profile_t4_col = <3>;
battery0_profile_t4 =
<
0       42820   4925
474     42510   5085
948     42181   5548
1423    41919   6185
1897    41721   6596
2371    41556   6912
2845    41413   7051
3320    41282   7127
3794    41156   7184
4268    41029   7232
4742    40903   7292
5217    40784   7361
5691    40657   7401
6165    40524   7440
6639    40392   7470
7114    40258   7469
7588    40121   7459
8062    39992   7426
8536    39866   7464
9011    39741   7453
9485    39623   7457
9959    39509   7475
10433   39399   7475
10908   39302   7475
11382   39206   7521
11856   39121   7524
12330   39038   7581
12805   38959   7620
13279   38884   7660
13753   38821   7699
14227   38748   7728
14702   38683   7784
15176   38620   7844
15650   38557   7883
16124   38493   7923
16598   38440   8000
17073   38387   8050
17547   38330   8066
18021   38279   8118
18495   38224   8164
18970   38177   8222
19444   38130   8276
19918   38092   8360
20392   38045   8400
20867   38005   8457
21341   37963   8534
21815   37931   8598
22289   37899   8702
22764   37868   8808
23238   37829   8910
23712   37792   9052
24186   37752   9236
24661   37711   9409
25135   37669   9581
25609   37615   9779
26083   37564   10007
26558   37508   10244
27032   37455   10472
27506   37381   10649
27980   37317   10871
28455   37254   11126
28929   37191   11366
29403   37131   11687
29877   37074   11981
30352   37026   12322
30826   36977   12599
31300   36920   13050
31774   36860   13431
32248   36780   13786
32723   36653   14163
33197   36481   14523
33671   36222   14878
34145   35831   15205
34620   35256   15756
35094   34414   16694
35568   33970   17200
36042   33970   17200
36517   33970   17200
36991   33970   17200
37465   33970   17200
37939   33970   17200
38414   33970   17200
38888   33970   17200
39362   33970   17200
39836   33970   17200
40311   33970   17200
40785   33970   17200
41259   33970   17200
41733   33970   17200
42208   33970   17200
42682   33970   17200
43156   33970   17200
43630   33970   17200
44105   33970   17200
44579   33970   17200
45053   33970   17200
45527   33970   17200
46002   33970   17200
46476   33970   17200
46950   33970   17200
>;
battery0_profile_t5_num = <100>;
battery0_profile_t5_col = <3>;
battery0_profile_t5 =
<
0       41440   10350
474     41121   10757
948     40854   11403
1423    40601   11861
1897    40343   12239
2371    40081   12541
2845    39827   13196
3320    39587   13974
3794    39388   14612
4268    39227   15008
4742    39093   15184
5217    38968   15323
5691    38867   15400
6165    38769   15446
6639    38678   15515
7114    38591   15594
7588    38512   15668
8062    38431   15700
8536    38352   15789
9011    38273   15878
9485    38201   15936
9959    38135   16068
10433   38065   16116
10908   38002   16246
11382   37936   16355
11856   37864   16474
12330   37791   16598
12805   37719   16736
13279   37640   16865
13753   37551   17023
14227   37467   17231
14702   37380   17471
15176   37285   17763
15650   37177   18042
16124   37066   18381
16598   36960   18724
17073   36834   19044
17547   36694   19373
18021   36512   19566
18495   36257   19781
18970   35857   19929
19444   35242   20255
19918   34210   20367
20392   33770   19450
20867   33770   19450
21341   33770   19450
21815   33770   19450
22289   33770   19450
22764   33770   19450
23238   33770   19450
23712   33770   19450
24186   33770   19450
24661   33770   19450
25135   33770   19450
25609   33770   19450
26083   33770   19450
26558   33770   19450
27032   33770   19450
27506   33770   19450
27980   33770   19450
28455   33770   19450
28929   33770   19450
29403   33770   19450
29877   33770   19450
30352   33770   19450
30826   33770   19450
31300   33770   19450
31774   33770   19450
32248   33770   19450
32723   33770   19450
33197   33770   19450
33671   33770   19450
34145   33770   19450
34620   33770   19450
35094   33770   19450
35568   33770   19450
36042   33770   19450
36517   33770   19450
36991   33770   19450
37465   33770   19450
37939   33770   19450
38414   33770   19450
38888   33770   19450
39362   33770   19450
39836   33770   19450
40311   33770   19450
40785   33770   19450
41259   33770   19450
41733   33770   19450
42208   33770   19450
42682   33770   19450
43156   33770   19450
43630   33770   19450
44105   33770   19450
44579   33770   19450
45053   33770   19450
45527   33770   19450
46002   33770   19450
46476   33770   19450
46950   33770   19450
>;
battery1_profile_t0_num = <100>;
battery1_profile_t0_col = <3>;
battery1_profile_t0 =
<
0       44010   600
475     43889   600
951     43778   621
1426    43667   600
1902    43566   625
2377    43455   625
2853    43354   625
3328    43243   625
3804    43132   625
4279    43019   618
4755    42901   621
5230    42785   614
5705    42669   625
6181    42558   640
6656    42437   630
7132    42318   631
7607    42205   634
8083    42085   626
8558    41968   637
9034    41852   650
9509    41739   650
9985    41625   650
10460   41507   650
10935   41396   650
11411   41285   650
11886   41174   650
12362   41073   669
12837   40962   650
13313   40861   665
13788   40760   675
14264   40655   664
14739   40559   675
15215   40455   675
15690   40360   675
16165   40274   698
16641   40180   700
17116   40086   702
17592   40000   708
18067   39917   731
18543   39829   729
19018   39744   750
19494   39649   750
19969   39500   710
20445   39334   645
20920   39206   625
21395   39119   641
21871   39033   625
22346   38964   637
22822   38896   625
23297   38832   625
23773   38769   625
24248   38714   625
24724   38657   636
25199   38599   625
25675   38552   640
26150   38502   645
26625   38446   625
27101   38405   641
27576   38360   650
28052   38313   650
28527   38275   650
29003   38228   650
29478   38193   658
29954   38153   652
30429   38120   662
30905   38078   650
31380   38053   683
31855   38015   675
32331   37983   675
32806   37947   689
33282   37890   650
33757   37810   625
34233   37723   625
34708   37667   644
35184   37616   641
35659   37571   648
36135   37519   637
36610   37467   625
37085   37419   625
37561   37382   625
38036   37343   625
38512   37301   636
38987   37249   625
39463   37186   625
39938   37114   625
40414   37059   625
40889   37002   641
41365   36913   625
41840   36849   612
42315   36839   625
42791   36823   625
43266   36810   632
43742   36801   650
44217   36771   636
44693   36715   674
45168   36478   650
45644   36064   675
46119   35523   675
46595   34773   685
47070   33690   750
>;
battery1_profile_t1_num = <100>;
battery1_profile_t1_col = <3>;
battery1_profile_t1 =
<
0       43900   800
475     43785   829
951     43680   829
1426    43577   850
1902    43476   850
2377    43365   850
2853    43264   875
3328    43152   873
3804    43032   850
4279    42922   850
4755    42802   829
5230    42690   875
5705    42569   875
6181    42452   850
6656    42335   870
7132    42216   869
7607    42095   875
8083    41984   875
8558    41863   863
9034    41752   897
9509    41632   875
9985    41518   875
10460   41407   875
10935   41296   900
11411   41186   877
11886   41084   900
12362   40976   906
12837   40872   904
13313   40771   925
13788   40670   925
14264   40569   925
14739   40470   929
15215   40375   950
15690   40280   967
16165   40194   973
16641   40100   975
17116   40015   1000
17592   39920   1000
18067   39835   1025
18543   39739   1025
19018   39636   1039
19494   39499   974
19969   39330   910
20445   39199   855
20920   39104   856
21395   39022   850
21871   38953   850
22346   38879   837
22822   38816   847
23297   38759   842
23773   38699   843
24248   38644   847
24724   38592   839
25199   38539   826
25675   38492   835
26150   38444   845
26625   38396   845
27101   38359   850
27576   38310   850
28052   38273   861
28527   38235   875
29003   38195   875
29478   38163   875
29954   38132   898
30429   38095   875
30905   38068   898
31380   38037   875
31855   38005   900
32331   37973   879
32806   37942   900
33282   37900   875
33757   37836   850
34233   37786   850
34708   37747   850
35184   37700   850
35659   37652   850
36135   37605   837
36610   37558   848
37085   37526   842
37561   37492   850
38036   37453   871
38512   37402   839
38987   37339   826
39463   37282   865
39938   37224   850
40414   37169   850
40889   37088   841
41365   37003   825
41840   36975   825
42315   36960   828
42791   36953   850
43266   36937   875
43742   36921   897
44217   36882   900
44693   36772   898
45168   36417   881
45644   35907   925
46119   35238   946
46595   34289   1052
47070   33850   1125
>;
battery1_profile_t2_num = <100>;
battery1_profile_t2_col = <3>;
battery1_profile_t2 =
<
0       43740   1325
475     43603   1354
951     43478   1375
1426    43375   1413
1902    43256   1400
2377    43145   1423
2853    43029   1425
3328    42913   1427
3804    42796   1433
4279    42672   1432
4755    42552   1429
5230    42435   1450
5705    42319   1450
6181    42198   1450
6656    42077   1455
7132    41966   1456
7607    41845   1459
8083    41734   1475
8558    41613   1475
9034    41502   1475
9509    41389   1475
9985    41278   1500
10460   41167   1500
10935   41056   1500
11411   40955   1525
11886   40851   1525
12362   40746   1531
12837   40642   1529
13313   40545   1560
13788   40450   1575
14264   40355   1589
14739   40260   1600
15215   40165   1619
15690   40073   1633
16165   39985   1650
16641   39890   1650
17116   39804   1675
17592   39693   1675
18067   39564   1637
18543   39406   1558
19018   39256   1464
19494   39149   1450
19969   39060   1450
20445   38981   1450
20920   38902   1431
21395   38836   1434
21871   38773   1450
22346   38714   1438
22822   38656   1447
23297   38599   1442
23773   38549   1468
24248   38494   1450
24724   38447   1475
25199   38399   1475
25675   38352   1475
26150   38314   1500
26625   38274   1500
27101   38233   1500
27576   38190   1500
28052   38159   1525
28527   38117   1521
29003   38085   1519
29478   38053   1525
29954   38022   1525
30429   38000   1562
30905   37968   1552
31380   37937   1558
31855   37905   1550
32331   37882   1571
32806   37842   1550
33282   37810   1575
33757   37768   1550
34233   37715   1525
34708   37675   1544
35184   37630   1550
35659   37591   1550
36135   37555   1562
36610   37517   1550
37085   37469   1567
37561   37419   1575
38036   37356   1596
38512   37292   1575
38987   37239   1600
39463   37170   1600
39938   37080   1600
40414   37024   1600
40889   36996   1600
41365   36981   1600
41840   36965   1638
42315   36948   1675
42791   36916   1693
43266   36857   1732
43742   36643   1772
44217   36199   1798
44693   35610   1853
45168   34796   2003
45644   33780   2250
46119   33780   2250
46595   33780   2250
47070   33780   2250
>;
battery1_profile_t3_num = <100>;
battery1_profile_t3_col = <3>;
battery1_profile_t3 =
<
0       43420   2275
475     43247   2333
951     43106   2404
1426    42980   2444
1902    42853   2475
2377    42735   2498
2853    42609   2513
3328    42492   2525
3804    42366   2525
4279    42242   2550
4755    42122   2550
5230    42005   2575
5705    41889   2600
6181    41772   2585
6656    41655   2575
7132    41536   2594
7607    41425   2625
8083    41314   2625
8558    41203   2650
9034    41092   2650
9509    40986   2668
9985    40878   2675
10460   40776   2698
10935   40671   2687
11411   40575   2725
11886   40471   2725
12362   40373   2744
12837   40279   2766
13313   40185   2800
13788   40090   2800
14264   39995   2825
14739   39900   2850
15215   39798   2850
15690   39693   2867
16165   39557   2827
16641   39400   2737
17116   39263   2698
17592   39143   2658
18067   39047   2656
18543   38959   2654
19018   38889   2650
19494   38820   2650
19969   38756   2675
20445   38695   2680
20920   38639   2700
21395   38579   2700
21871   38532   2723
22346   38474   2713
22822   38427   2750
23297   38379   2750
23773   38332   2775
24248   38284   2797
24724   38247   2811
25199   38199   2826
25675   38162   2850
26150   38126   2880
26625   38094   2900
27101   38056   2909
27576   38020   2925
28052   37999   2950
28527   37967   2975
29003   37943   2994
29478   37913   3000
29954   37891   3023
30429   37860   3013
30905   37838   3050
31380   37813   3067
31855   37785   3075
32331   37745   3075
32806   37707   3075
33282   37660   3100
33757   37618   3115
34233   37585   3154
34708   37545   3175
35184   37496   3200
35659   37433   3223
36135   37369   3263
36610   37307   3303
37085   37246   3342
37561   37177   3407
38036   37080   3446
38512   37007   3508
38987   36970   3626
39463   36938   3721
39938   36916   3894
40414   36884   4092
40889   36839   4357
41365   36782   4785
41840   36589   5312
42315   36179   6114
42791   35582   7654
43266   34776   11769
43742   33790   19550
44217   33790   19550
44693   33790   19550
45168   33790   19550
45644   33790   19550
46119   33790   19550
46595   33790   19550
47070   33790   19550
>;
battery1_profile_t4_num = <100>;
battery1_profile_t4_col = <3>;
battery1_profile_t4 =
<
0       42760   4900
475     42510   5017
951     42345   5238
1426    42202   5319
1902    42063   5383
2377    41936   5423
2853    41809   5463
3328    41692   5500
3804    41566   5517
4279    41452   5538
4755    41332   5554
5230    41220   5575
5705    41109   5600
6181    40998   5625
6656    40887   5675
7132    40776   5675
7607    40669   5709
8083    40564   5725
8558    40458   5726
9034    40353   5728
9509    40249   5750
9985    40151   5783
10460   40056   5800
10935   39951   5800
11411   39855   5825
11886   39738   5809
12362   39621   5794
12837   39486   5734
13313   39357   5690
13788   39230   5675
14264   39119   5661
14739   39020   5654
15215   38933   5675
15690   38853   5692
16165   38783   5725
16641   38710   5725
17116   38647   5752
17592   38593   5775
18067   38532   5806
18543   38476   5825
19018   38427   5871
19494   38380   5876
19969   38332   5925
20445   38285   5930
20920   38245   5969
21395   38199   5984
21871   38161   6047
22346   38120   6076
22822   38087   6100
23297   38046   6117
23773   38014   6182
24248   37991   6222
24724   37961   6261
25199   37930   6301
25675   37914   6356
26150   37888   6385
26625   37872   6445
27101   37846   6484
27576   37830   6549
28052   37809   6614
28527   37787   6679
29003   37755   6737
29478   37713   6800
29954   37673   6873
30429   37635   6987
30905   37588   7104
31380   37540   7217
31855   37480   7344
32331   37417   7505
32806   37353   7703
33282   37280   7876
33757   37216   8128
34233   37139   8401
34708   37044   8696
35184   36966   9028
35659   36912   9454
36135   36875   9942
36610   36837   10570
37085   36796   11369
37561   36752   12493
38036   36687   14154
38512   36544   17316
38987   36223   24383
39463   35704   24407
39938   34945   22663
40414   33980   20150
40889   33980   20150
41365   33980   20150
41840   33980   20150
42315   33980   20150
42791   33980   20150
43266   33980   20150
43742   33980   20150
44217   33980   20150
44693   33980   20150
45168   33980   20150
45644   33980   20150
46119   33980   20150
46595   33980   20150
47070   33980   20150
>;
battery1_profile_t5_num = <100>;
battery1_profile_t5_col = <3>;
battery1_profile_t5 =
<
0       41490   8600
475     41125   8907
951     40891   9488
1426    40725   9807
1902    40569   9984
2377    40436   10142
2853    40299   10250
3328    40173   10357
3804    40056   10442
4279    39939   10532
4755    39821   10592
5230    39705   10636
5705    39589   10700
6181    39462   10740
6656    39345   10780
7132    39218   10781
7607    39095   10793
8083    38984   10801
8558    38888   10863
9034    38794   10903
9509    38713   10925
9985    38644   10975
10460   38574   11020
10935   38521   11087
11411   38458   11103
11886   38404   11150
12362   38353   11231
12837   38305   11291
13313   38258   11335
13788   38210   11375
14264   38178   11468
14739   38137   11537
15215   38105   11619
15690   38073   11692
16165   38042   11771
16641   38020   11850
17116   37989   11932
17592   37973   12050
18067   37947   12132
18543   37923   12309
19018   37901   12421
19494   37880   12526
19969   37854   12660
20445   37828   12718
20920   37805   12858
21395   37773   13010
21871   37741   13169
22346   37710   13365
22822   37668   13541
23297   37629   13761
23773   37582   13991
24248   37534   14251
24724   37477   14539
25199   37419   14807
25675   37355   15148
26150   37292   15500
26625   37221   15877
27101   37142   16277
27576   37061   16746
28052   36997   17286
28527   36935   17896
29003   36895   18665
29478   36853   19670
29954   36813   20973
30429   36765   23070
30905   36708   26509
31380   36624   26590
31855   36420   26148
32331   33990   20000
32806   33990   20000
33282   33990   20000
33757   33990   20000
34233   33990   20000
34708   33990   20000
35184   33990   20000
35659   33990   20000
36135   33990   20000
36610   33990   20000
37085   33990   20000
37561   33990   20000
38036   33990   20000
38512   33990   20000
38987   33990   20000
39463   33990   20000
39938   33990   20000
40414   33990   20000
40889   33990   20000
41365   33990   20000
41840   33990   20000
42315   33990   20000
42791   33990   20000
43266   33990   20000
43742   33990   20000
44217   33990   20000
44693   33990   20000
45168   33990   20000
45644   33990   20000
46119   33990   20000
46595   33990   20000
47070   33990   20000
>;
battery2_profile_t0_num = <100>;
battery2_profile_t0_col = <3>;
battery2_profile_t0 =
<
0       44000   600
486     43838   584
973     43698   594
1459    43570   597
1945    43444   600
2432    43320   600
2918    43207   600
3405    43083   610
3891    42970   625
4377    42846   616
4864    42720   600
5350    42597   623
5836    42474   625
6323    42349   621
6809    42227   600
7295    42103   625
7782    41980   625
8268    41857   625
8755    41740   625
9241    41618   625
9727    41503   638
10214   41381   629
10700   41276   650
11186   41152   625
11673   41047   650
12159   40934   650
12645   40830   650
13132   40726   650
13618   40618   663
14105   40511   629
14591   40412   650
15077   40315   661
15564   40217   651
16050   40127   675
16536   40036   682
17023   39945   677
17509   39858   687
17995   39771   700
18482   39690   700
18968   39609   725
19455   39528   726
19941   39457   750
20427   39363   750
20914   39247   727
21400   39079   661
21886   38949   650
22373   38860   630
22859   38783   636
23345   38718   650
23832   38653   633
24318   38590   608
24805   38542   649
25291   38483   625
25777   38434   625
26264   38386   625
26750   38341   611
27236   38298   625
27723   38256   643
28209   38213   633
28695   38171   626
29182   38139   650
29668   38106   650
30155   38066   650
30641   38036   650
31127   38008   673
31614   37976   650
32100   37953   675
32586   37921   675
33073   37898   675
33559   37868   680
34045   37843   679
34532   37776   626
35018   37695   623
35505   37621   618
35991   37580   625
36477   37541   625
36964   37492   625
37450   37445   606
37936   37404   625
38423   37370   625
38909   37338   625
39395   37306   625
39882   37260   625
40368   37200   625
40855   37135   615
41341   37073   625
41827   37016   625
42314   36936   625
42800   36858   623
43286   36840   618
43773   36826   625
44259   36810   625
44745   36804   650
45232   36775   656
45718   36717   675
46205   36504   662
46691   36096   675
47177   35530   694
47664   34774   744
48150   33660   825
>;
battery2_profile_t1_num = <100>;
battery2_profile_t1_col = <3>;
battery2_profile_t1 =
<
0       43890   800
486     43750   816
973     43623   806
1459    43510   825
1945    43394   825
2432    43270   825
2918    43157   825
3405    43039   825
3891    42920   825
4377    42796   825
4864    42672   825
5350    42548   825
5836    42424   838
6323    42300   829
6809    42179   831
7295    42059   850
7782    41930   825
8268    41814   842
8755    41690   832
9241    41577   850
9727    41463   850
10214   41341   832
10700   41229   856
11186   41116   860
11673   41007   875
12159   40894   858
12645   40790   875
13132   40686   875
13618   40583   887
14105   40481   900
14591   40382   900
15077   40285   900
15564   40188   901
16050   40100   925
16536   40013   943
17023   39925   948
17509   39843   963
17995   39759   975
18482   39670   975
18968   39589   1000
19455   39507   1000
19941   39417   1017
20427   39307   1010
20914   39168   929
21400   39025   886
21886   38909   845
22373   38820   825
22859   38743   825
23345   38678   824
23832   38620   817
24318   38567   817
24805   38512   824
25291   38463   825
25777   38414   825
26264   38366   805
26750   38327   814
27236   38279   801
27723   38246   825
28209   38203   825
28695   38171   825
29182   38139   839
29668   38106   850
30155   38074   850
30641   38041   825
31127   38018   850
31614   37993   850
32100   37967   850
32586   37941   874
33073   37918   861
33559   37896   870
34045   37872   871
34532   37836   850
35018   37787   825
35505   37746   825
35991   37710   817
36477   37671   800
36964   37632   810
37450   37585   806
37936   37553   825
38423   37520   825
38909   37488   802
39395   37448   807
39882   37400   808
40368   37340   800
40855   37275   800
41341   37221   819
41827   37164   821
42314   37081   813
42800   36998   800
43286   36973   800
43773   36960   819
44259   36950   850
44745   36934   850
45232   36905   856
45718   36856   875
46205   36664   875
46691   36245   880
47177   35647   944
47664   34839   1047
48150   33630   1350
>;
battery2_profile_t2_num = <100>;
battery2_profile_t2_col = <3>;
battery2_profile_t2 =
<
0       43700   1225
486     43540   1256
973     43411   1294
1459    43290   1297
1945    43166   1300
2432    43043   1300
2918    42922   1300
3405    42796   1300
3891    42672   1300
4377    42549   1315
4864    42425   1305
5350    42303   1325
5836    42178   1336
6323    42055   1325
6809    41934   1325
7295    41815   1325
7782    41694   1325
8268    41581   1350
8755    41457   1350
9241    41342   1350
9727    41228   1350
10214   41115   1352
10700   41011   1375
11186   40898   1367
11673   40793   1397
12159   40686   1389
12645   40587   1420
13132   40482   1400
13618   40384   1425
14105   40287   1425
14591   40197   1442
15077   40105   1457
15564   40015   1475
16050   39923   1463
16536   39842   1479
17023   39753   1481
17509   39676   1515
17995   39589   1525
18482   39508   1541
18968   39414   1550
19455   39308   1528
19941   39180   1475
20427   39040   1397
20914   38918   1338
21400   38822   1316
21886   38741   1300
22373   38676   1300
22859   38611   1300
23345   38554   1300
23832   38496   1287
24318   38447   1300
24805   38399   1300
25291   38350   1300
25777   38311   1324
26264   38263   1314
26750   38226   1330
27236   38185   1329
27723   38150   1337
28209   38118   1350
28695   38086   1350
29182   38053   1350
29668   38021   1350
30155   37994   1365
30641   37968   1355
31127   37944   1375
31614   37926   1386
32100   37899   1375
32586   37883   1392
33073   37864   1392
33559   37841   1398
34045   37819   1386
34532   37798   1400
35018   37774   1380
35505   37742   1390
35991   37699   1351
36477   37660   1359
36964   37614   1350
37450   37582   1350
37936   37550   1375
38423   37516   1375
38909   37467   1375
39395   37415   1390
39882   37350   1400
40368   37291   1400
40855   37230   1400
41341   37157   1400
41827   37065   1412
42314   37018   1447
42800   36985   1425
43286   36966   1468
43773   36940   1500
44259   36912   1565
44745   36869   1666
45232   36763   1830
45718   36422   2160
46205   35819   3702
46691   34746   10871
47177   31130   6775
47664   31130   6775
48150   31130   6775
>;
battery2_profile_t3_num = <100>;
battery2_profile_t3_col = <3>;
battery2_profile_t3 =
<
0       43400   1950
486     43198   2028
973     43048   2125
1459    42911   2168
1945    42779   2188
2432    42649   2225
2918    42519   2225
3405    42389   2225
3891    42260   2250
4377    42140   2259
4864    42012   2275
5350    41888   2275
5836    41768   2287
6323    41650   2304
6809    41529   2306
7295    41413   2325
7782    41300   2325
8268    41184   2350
8755    41070   2375
9241    40957   2375
9727    40849   2413
10214   40740   2400
10700   40634   2419
11186   40532   2440
11673   40427   2450
12159   40330   2467
12645   40233   2482
13132   40136   2500
13618   40048   2525
14105   39953   2529
14591   39870   2570
15077   39779   2586
15564   39697   2600
16050   39607   2617
16536   39513   2625
17023   39415   2625
17509   39288   2587
17995   39145   2516
18482   39016   2455
18968   38894   2400
19455   38808   2400
19941   38727   2400
20427   38658   2418
20914   38594   2400
21400   38527   2425
21886   38474   2430
22373   38426   2450
22859   38371   2461
23345   38328   2500
23832   38280   2500
24318   38240   2525
24805   38192   2525
25291   38153   2550
25777   38116   2575
26264   38084   2575
26750   38051   2611
27236   38019   2625
27723   37986   2643
28209   37957   2658
28695   37931   2675
29182   37909   2700
29668   37888   2730
30155   37872   2750
30641   37855   2773
31127   37839   2777
31614   37823   2800
32100   37807   2808
32586   37790   2849
33073   37768   2850
33559   37746   2875
34045   37705   2875
34532   37666   2925
35018   37618   2930
35505   37579   2975
35991   37540   3017
36477   37491   3050
36964   37436   3140
37450   37368   3206
37936   37296   3289
38423   37231   3384
38909   37155   3535
39395   37067   3733
39882   36963   3959
40368   36900   4348
40855   36845   4936
41341   36791   6025
41827   36717   8015
42314   36616   12548
42800   36417   15848
43286   33120   11595
43773   31960   9525
44259   31960   9525
44745   31960   9525
45232   31960   9525
45718   31960   9525
46205   31960   9525
46691   31960   9525
47177   31960   9525
47664   31960   9525
48150   31960   9525
>;
battery2_profile_t4_num = <100>;
battery2_profile_t4_col = <3>;
battery2_profile_t4 =
<
0       42910   3350
486     42583   3490
973     42396   3699
1459    42234   3797
1945    42086   3849
2432    41952   3905
2918    41822   3968
3405    41692   4000
3891    41562   4024
4377    41443   4040
4864    41323   4075
5350    41202   4075
5836    41088   4111
6323    40975   4148
6809    40861   4142
7295    40758   4175
7782    40644   4175
8268    40541   4200
8755    40439   4230
9241    40332   4250
9727    40238   4289
10214   40145   4300
10700   40048   4318
11186   39954   4333
11673   39863   4350
12159   39776   4400
12645   39689   4425
13132   39600   4445
13618   39504   4461
14105   39407   4474
14591   39293   4450
15077   39167   4393
15564   39037   4352
16050   38923   4325
16536   38821   4304
17023   38723   4306
17509   38650   4300
17995   38579   4325
18482   38514   4325
18968   38460   4357
19455   38404   4397
19941   38355   4413
20427   38306   4453
20914   38258   4475
21400   38213   4518
21886   38170   4525
22373   38132   4575
22859   38095   4612
23345   38063   4671
23832   38031   4712
24318   37998   4750
24805   37966   4768
25291   37937   4808
25777   37920   4849
26264   37894   4889
26750   37878   4925
27236   37862   4966
27723   37855   5024
28209   37839   5077
28695   37823   5136
29182   37807   5208
29668   37790   5273
30155   37774   5369
30641   37748   5440
31127   37724   5541
31614   37687   5647
32100   37648   5778
32586   37606   5911
33073   37561   6064
33559   37512   6266
34045   37453   6497
34532   37391   6751
35018   37318   7034
35505   37243   7389
35991   37178   7861
36477   37091   8397
36964   36990   9121
37450   36895   10152
37936   36809   11790
38423   36744   14410
38909   36657   17006
39395   36469   19622
39882   32360   14225
40368   32360   14225
40855   32360   14225
41341   32360   14225
41827   32360   14225
42314   32360   14225
42800   32360   14225
43286   32360   14225
43773   32360   14225
44259   32360   14225
44745   32360   14225
45232   32360   14225
45718   32360   14225
46205   32360   14225
46691   32360   14225
47177   32360   14225
47664   32360   14225
48150   32360   14225
>;
battery2_profile_t5_num = <100>;
battery2_profile_t5_col = <3>;
battery2_profile_t5 =
<
0       41950   6775
486     41582   6977
973     41316   7455
1459    41106   7755
1945    40946   7961
2432    40802   8083
2918    40672   8205
3405    40546   8276
3891    40422   8349
4377    40309   8405
4864    40195   8455
5350    40082   8517
5836    39978   8561
6323    39875   8625
6809    39768   8660
7295    39668   8700
7782    39564   8723
8268    39451   8739
8755    39345   8770
9241    39222   8771
9727    39108   8750
10214   38994   8775
10700   38888   8775
11186   38791   8750
11673   38703   8797
12159   38627   8839
12645   38553   8855
13132   38488   8895
13618   38433   8961
14105   38378   9000
14591   38320   9050
15077   38271   9107
15564   38232   9171
16050   38184   9213
16536   38145   9300
17023   38104   9339
17509   38068   9410
17995   38040   9476
18482   38007   9525
18968   37985   9613
19455   37961   9694
19941   37935   9763
20427   37919   9856
20914   37903   9956
21400   37876   10053
21886   37860   10149
22373   37844   10296
22859   37818   10423
23345   37801   10585
23832   37775   10759
24318   37748   10937
24805   37723   11139
25291   37687   11350
25777   37651   11570
26264   37613   11797
26750   37574   12080
27236   37534   12364
27723   37476   12633
28209   37426   12969
28695   37368   13312
29182   37306   13718
29668   37242   14236
30155   37161   14743
30641   37090   15452
31127   37009   16303
31614   36928   17384
32100   36867   18682
32586   36802   20163
33073   36718   22181
33559   36586   24968
34045   36251   25652
34532   32510   16300
35018   32510   16300
35505   32510   16300
35991   32510   16300
36477   32510   16300
36964   32510   16300
37450   32510   16300
37936   32510   16300
38423   32510   16300
38909   32510   16300
39395   32510   16300
39882   32510   16300
40368   32510   16300
40855   32510   16300
41341   32510   16300
41827   32510   16300
42314   32510   16300
42800   32510   16300
43286   32510   16300
43773   32510   16300
44259   32510   16300
44745   32510   16300
45232   32510   16300
45718   32510   16300
46205   32510   16300
46691   32510   16300
47177   32510   16300
47664   32510   16300
48150   32510   16300
>;
battery3_profile_t0_num = <100>;
battery3_profile_t0_col = <3>;
battery3_profile_t0 =
<
0       44000   650
475     43863   650
950     43748   675
1425    43638   675
1899    43527   675
2374    43404   651
2849    43293   675
3324    43182   675
3799    43064   675
4274    42950   675
4748    42831   675
5223    42709   675
5698    42588   676
6173    42469   684
6648    42352   700
7123    42225   680
7598    42109   690
8072    41992   699
8547    41871   689
9022    41750   679
9497    41639   700
9972    41526   692
10447   41408   697
10922   41297   700
11396   41186   700
11871   41075   700
12346   40965   700
12821   40862   720
13296   40753   715
13771   40652   724
14245   40547   725
14720   40442   703
15195   40347   725
15670   40252   725
16145   40157   725
16620   40067   750
17095   39977   750
17569   39888   766
18044   39798   781
18519   39710   779
18994   39615   775
19469   39510   775
19944   39372   746
20418   39227   721
20893   39108   700
21368   39014   675
21843   38934   675
22318   38855   663
22793   38787   673
23268   38724   666
23742   38670   675
24217   38607   675
24692   38547   661
25167   38499   674
25642   38442   665
26117   38394   675
26592   38347   675
27066   38299   675
27541   38252   675
28016   38214   687
28491   38177   700
28966   38136   700
29441   38095   700
29915   38063   700
30390   38031   712
30865   37989   700
31340   37957   700
31815   37928   730
32290   37896   730
32765   37869   740
33239   37811   701
33714   37725   675
34189   37643   654
34664   37588   675
35139   37540   675
35614   37502   675
36088   37450   663
36563   37408   675
37038   37360   675
37513   37325   675
37988   37293   675
38463   37258   690
38938   37200   675
39412   37146   675
39887   37082   675
40362   37027   675
40837   36966   675
41312   36884   675
41787   36825   663
42262   36809   675
42736   36800   692
43211   36787   700
43686   36771   700
44161   36741   712
44636   36675   700
45111   36453   700
45585   36055   705
46060   35540   745
46535   34819   760
47010   33820   825
>;
battery3_profile_t1_num = <100>;
battery3_profile_t1_col = <3>;
battery3_profile_t1 =
<
0       43860   925
475     43729   954
950     43618   979
1425    43508   981
1899    43397   983
2374    43286   1000
2849    43175   1000
3324    43054   1000
3799    42937   1000
4274    42820   994
4748    42702   996
5223    42577   975
5698    42460   1000
6173    42340   975
6648    42217   975
7123    42098   994
7598    41977   975
8072    41866   975
8547    41746   975
9022    41625   975
9497    41512   975
9972    41401   1000
10447   41290   979
10922   41179   1000
11396   41069   1000
11871   40958   1000
12346   40847   1000
12821   40744   1019
13296   40639   1025
13771   40544   1025
14245   40444   1037
14720   40344   1050
15195   40249   1050
15670   40154   1050
16145   40059   1050
16620   39968   1075
17095   39879   1075
17569   39794   1100
18044   39699   1100
18519   39604   1100
18994   39482   1066
19469   39337   1004
19944   39204   950
20418   39084   925
20893   38996   925
21368   38917   925
21843   38838   904
22318   38773   900
22793   38710   900
23268   38652   900
23742   38595   900
24217   38547   919
24692   38490   900
25167   38442   900
25642   38395   900
26117   38348   902
26592   38310   925
27066   38272   925
27541   38224   925
28016   38186   925
28491   38149   925
28966   38118   940
29441   38086   950
29915   38054   950
30390   38016   934
30865   37991   950
31340   37959   950
31815   37929   953
32290   37899   958
32765   37864   950
33239   37824   928
33714   37777   925
34189   37729   924
34664   37688   915
35139   37644   920
35614   37597   900
36088   37553   900
36563   37512   876
37038   37489   900
37513   37458   925
37988   37419   908
38463   37372   925
38938   37316   925
39412   37252   925
39887   37199   925
40362   37146   925
40837   37069   920
41312   36989   919
41787   36956   925
42262   36950   948
42736   36935   950
43211   36919   953
43686   36896   958
44161   36857   975
44636   36726   975
45111   36378   975
45585   35890   1026
46060   35245   1082
46535   34357   1177
47010   33770   1275
>;
battery3_profile_t2_num = <100>;
battery3_profile_t2_col = <3>;
battery3_profile_t2 =
<
0       43630   1750
475     43468   1794
950     43337   1875
1425    43218   1894
1899    43091   1900
2374    42964   1900
2849    42848   1900
3324    42722   1903
3799    42604   1908
4274    42480   1907
4748    42361   1903
5223    42237   1912
5698    42115   1900
6173    41995   1900
6648    41874   1900
7123    41763   1900
7598    41643   1900
8072    41529   1900
8547    41409   1900
9022    41298   1900
9497    41187   1900
9972    41076   1900
10447   40965   1900
10922   40865   1900
11396   40764   1925
11871   40653   1908
12346   40552   1925
12821   40448   1947
13296   40348   1950
13771   40248   1950
14245   40153   1965
14720   40058   1970
15195   39963   1970
15670   39877   1984
16145   39781   2000
16620   39686   2000
17095   39578   1996
17569   39451   1957
18044   39312   1892
18519   39178   1830
18994   39066   1788
19469   38976   1798
19944   38888   1775
20418   38818   1769
20893   38746   1750
21368   38683   1750
21843   38620   1750
22318   38566   1760
22793   38515   1754
23268   38460   1756
23742   38409   1775
24217   38361   1775
24692   38314   1786
25167   38276   1822
25642   38229   1800
26117   38191   1825
26592   38153   1825
27066   38116   1838
27541   38079   1827
28016   38047   1850
28491   38015   1850
28966   37984   1850
29441   37952   1865
29915   37920   1850
30390   37898   1875
30865   37868   1880
31340   37845   1881
31815   37813   1875
32290   37791   1898
32765   37760   1887
33239   37727   1898
33714   37686   1875
34189   37641   1875
34664   37602   1897
35139   37571   1900
35614   37529   1876
36088   37497   1916
36563   37454   1925
37038   37397   1925
37513   37334   1935
37988   37280   1975
38463   37227   1989
38938   37162   2004
39412   37076   2025
39887   37003   2033
40362   36971   2050
40837   36955   2113
41312   36938   2153
41787   36913   2209
42262   36882   2289
42736   36817   2389
43211   36630   2486
43686   36222   2582
44161   35655   2811
44636   34896   3207
45111   33754   4021
45585   33590   4150
46060   33590   4150
46535   33590   4150
47010   33590   4150
>;
battery3_profile_t3_num = <100>;
battery3_profile_t3_col = <3>;
battery3_profile_t3 =
<
0       43190   3375
475     42966   3477
950     42807   3612
1425    42673   3675
1899    42541   3709
2374    42414   3749
2849    42288   3750
3324    42161   3750
3799    42034   3750
4274    41918   3775
4748    41800   3797
5223    41677   3787
5698    41556   3752
6173    41445   3775
6648    41332   3769
7123    41213   3770
7598    41103   3785
8072    40989   3800
8547    40885   3805
9022    40780   3804
9497    40677   3825
9972    40570   3833
10447   40465   3850
10922   40365   3850
11396   40253   3825
11871   40158   3843
12346   40063   3850
12821   39968   3850
13296   39873   3850
13771   39778   3874
14245   39673   3850
14720   39561   3844
15195   39435   3805
15670   39298   3740
16145   39171   3700
16620   39056   3675
17095   38953   3654
17569   38873   3675
18044   38794   3667
18519   38723   3650
18994   38659   3675
19469   38597   3675
19944   38543   3675
20418   38482   3675
20893   38435   3696
21368   38386   3725
21843   38339   3750
22318   38291   3750
22793   38244   3755
23268   38196   3775
23742   38159   3800
24217   38121   3824
24692   38079   3839
25167   38047   3875
25642   38008   3875
26117   37984   3925
26592   37952   3948
27066   37920   3950
27541   37889   3950
28016   37873   3967
28491   37847   3975
28966   37831   3996
29441   37811   4025
29915   37790   4050
30390   37768   4090
30865   37738   4109
31340   37715   4169
31815   37673   4184
32290   37641   4270
32765   37599   4302
33239   37556   4378
33714   37516   4454
34189   37461   4540
34664   37405   4641
35139   37341   4735
35614   37277   4856
36088   37214   4991
36563   37145   5143
37038   37059   5303
37513   36979   5491
37988   36930   5724
38463   36888   5990
38938   36856   6348
39412   36817   6782
39887   36766   7343
40362   36693   8094
40837   36532   9027
41312   36219   10214
41787   35712   12312
42262   35011   16158
42736   34062   20182
43211   33620   19150
43686   33620   19150
44161   33620   19150
44636   33620   19150
45111   33620   19150
45585   33620   19150
46060   33620   19150
46535   33620   19150
47010   33620   19150
>;
battery3_profile_t4_num = <100>;
battery3_profile_t4_col = <3>;
battery3_profile_t4 =
<
0       42350   7800
475     42100   7960
950     41925   8192
1425    41783   8312
1899    41647   8375
2374    41514   8375
2849    41388   8400
3324    41271   8400
3799    41151   8417
4274    41030   8425
4748    40920   8425
5223    40807   8412
5698    40696   8427
6173    40579   8450
6648    40452   8444
7123    40325   8425
7598    40209   8425
8072    40089   8400
8547    39979   8360
9022    39870   8350
9497    39759   8312
9972    39646   8300
10447   39535   8277
10922   39415   8225
11396   39302   8194
11871   39191   8132
12346   39083   8100
12821   38988   8078
13296   38903   8075
13771   38819   8051
14245   38749   8060
14720   38681   8081
15195   38617   8100
15670   38554   8110
16145   38491   8100
16620   38437   8139
17095   38386   8175
17569   38338   8193
18044   38280   8192
18519   38241   8225
18994   38195   8238
19469   38148   8255
19944   38110   8300
20418   38072   8300
20893   38033   8321
21368   38001   8362
21843   37969   8376
22318   37944   8416
22793   37918   8455
23268   37902   8515
23742   37876   8569
24217   37850   8625
24692   37829   8714
25167   37807   8833
25642   37775   8930
26117   37750   9049
26592   37712   9168
27066   37680   9336
27541   37638   9516
28016   37599   9736
28491   37552   9959
28966   37504   10242
29441   37447   10462
29915   37389   10778
30390   37326   11070
30865   37261   11399
31340   37198   11755
31815   37135   12171
32290   37071   12566
32765   37008   13001
33239   36955   13468
33714   36899   14000
34189   36853   14607
34664   36813   15217
35139   36745   15861
35614   36654   16482
36088   36524   17065
36563   36306   17523
37038   35956   18114
37513   35418   19679
37988   34619   21564
38463   33730   19325
38938   33730   19325
39412   33730   19325
39887   33730   19325
40362   33730   19325
40837   33730   19325
41312   33730   19325
41787   33730   19325
42262   33730   19325
42736   33730   19325
43211   33730   19325
43686   33730   19325
44161   33730   19325
44636   33730   19325
45111   33730   19325
45585   33730   19325
46060   33730   19325
46535   33730   19325
47010   33730   19325
>;
battery3_profile_t5_num = <100>;
battery3_profile_t5_col = <3>;
battery3_profile_t5 =
<
0       40770   11875
475     40409   12400
950     40135   13500
1425    39905   14212
1899    39696   14819
2374    39516   15309
2849    39362   15643
3324    39221   15861
3799    39094   16002
4274    38970   16064
4748    38860   16122
5223    38761   16162
5698    38676   16202
6173    38594   16273
6648    38521   16336
7123    38458   16395
7598    38394   16435
8072    38340   16500
8547    38282   16555
9022    38235   16629
9497    38187   16688
9972    38140   16733
10447   38102   16819
10922   38065   16925
11396   38018   17007
11871   37980   17125
12346   37932   17250
12821   37884   17390
13296   37822   17545
13771   37759   17704
14245   37695   17902
14720   37630   18155
15195   37551   18393
15670   37472   18605
16145   37393   18842
16620   37313   19093
17095   37233   19376
17569   37153   19616
18044   37087   19880
18519   37024   20179
18994   36961   20472
19469   36897   20731
19944   36811   20906
20418   36684   20995
20893   36500   21113
21368   36193   21268
21843   35736   21477
22318   35010   21838
22793   33934   19861
23268   33830   19600
23742   33830   19600
24217   33830   19600
24692   33830   19600
25167   33830   19600
25642   33830   19600
26117   33830   19600
26592   33830   19600
27066   33830   19600
27541   33830   19600
28016   33830   19600
28491   33830   19600
28966   33830   19600
29441   33830   19600
29915   33830   19600
30390   33830   19600
30865   33830   19600
31340   33830   19600
31815   33830   19600
32290   33830   19600
32765   33830   19600
33239   33830   19600
33714   33830   19600
34189   33830   19600
34664   33830   19600
35139   33830   19600
35614   33830   19600
36088   33830   19600
36563   33830   19600
37038   33830   19600
37513   33830   19600
37988   33830   19600
38463   33830   19600
38938   33830   19600
39412   33830   19600
39887   33830   19600
40362   33830   19600
40837   33830   19600
41312   33830   19600
41787   33830   19600
42262   33830   19600
42736   33830   19600
43211   33830   19600
43686   33830   19600
44161   33830   19600
44636   33830   19600
45111   33830   19600
45585   33830   19600
46060   33830   19600
46535   33830   19600
47010   33830   19600
>;

/* battery_prop_dim2_ext.dtsi */
/*vboot voltage for gauge 0%*/
g_PMIC_MIN_VOL_row = <4>;
g_PMIC_MIN_VOL_col = <10>;
g_PMIC_MIN_VOL =
<
	32700  32700  32700  32700
	32700  32700  32700  32700
	32700  32700  32700  32700
	32200  32200  32200  32200
	31000  31000  31000  31000
	31500  31500  31500  31500
	31000  31000  31000  31000
	31000  31000  31000  31000
	31000  31000  31000  31000
	31000  31000  31000  31200
>;
/*boot_up current for gauge 0%*/
g_PON_SYS_IBOOT_row = <4>;
g_PON_SYS_IBOOT_col = <10>;
g_PON_SYS_IBOOT =
<
	5000  5000  5000  5000
	5000  5000  5000  5000
	5000  5000  5000  5000
	5000  5000  5000  5000
	5000  5000  5000  5000
	5000  5000  5000  5000
	5000  5000  5000  5000
	5000  5000  5000  5000
	5000  5000  5000  5000
	5000  5000  5000  5000
>;
/*Pseudo1 hide percentage*/
g_QMAX_SYS_VOL_row = <4>;
g_QMAX_SYS_VOL_col = <10>;
g_QMAX_SYS_VOL =
<
	33600  33600  33600  33600
	33600  33600  33600  33600
	33600  33600  33600  33600
	33600  33600  33600  33600
	33600  33600  33600  33600
	32500  32500  32500  32500
	32800  32800  32800  32800
	32800  32800  32800  32800
	32800  32800  32800  32800
	32800  32800  32800  32800
>;
/*Pseudo100 percentage setting*/
g_FG_PSEUDO100_row = <4>;
g_FG_PSEUDO100_col = <10>;
g_FG_PSEUDO100 =
<
	92  92  92  90
	92  92  92  90
	92  92  92  90
	92  92  92  90
	92  92  92  90
	92  92  92  90
	92  92  92  90
	92  92  92  90
	92  92  92  90
	92  92  92  90
>;

	};
};

/* #include "../abc_spec_manager_type1.dtsi" */      /* From abc_spec_manager_type1.py */
&smd {
	sec_abc {
		compatible = "samsung,sec_abc";
		status = "okay";
		abc_spec_type1 {
			module_list = "gpu", "gpu_qc", "gpu_qc", "camera", "camera", "vib";
			name_list = "gpu_fault", "gpu_fault", "gpu_page_fault", "mipi_overflow", "i2c_fail", "int_gnd_short";
#ifndef CONFIG_SEC_FACTORY
			threshold_cnt = <20>, <2>, <20>, <1>, <1>, <25>;
			threshold_time = <1200>, <1200>, <1200>, <0>, <0>, <5>;
#else
			threshold_cnt = <20>, <2>, <20>, <1>, <1>, <25>;
			threshold_time = <1200>, <1200>, <1200>, <0>, <0>, <5>;
#endif
		};
	};
};

/* #include "../ap_mtk_mt6877_T.dtsi" */             /* From ap_mtk_mt6877_T.py */
#include <dt-bindings/clock/mt6877-clk.h>
/* /home/dpi/qb5_8814/workspace/P4_1716/android/kernel/kmodule/ap/mtk/mt6877/ap_mtk_mt6877_T.m53x_eur.04.dtsi */

#include "../../mediatek/k6877v1_64_titan_syberian_tiger_k419/Board_00.dts"
#include "../../mediatek/k6877v1_64_titan_syberian_tiger_k419/gpio_04.dtsi"


/* #include "../abc_common.dtsi" */                  /* From abc_common.py */
&smd {
	abc_hub {
		compatible = "samsung,abc_hub";
		status = "okay";
		bootc {
			bootc,time_spec_user = <100000>; /* user binary user build */
			bootc,time_spec_eng = <150000>; /* user binary eng build */
			bootc,time_spec_fac = <100000>; /* factory binary */
		};
	};
};

/* #include "../i2c-gpio.dtsi" */                    /* From i2c-gpio.py */
&pio {
       gpio_i2c_0_sda {
               gpio_i2c_0_sda_default: gpio_i2c_0_sda_default {
                       GPIO_CONFIG_PUD_DRV(AP,pio,157, FUNC_INPUT, PULL_NONE, DRV_LV1);
               };
       };
};

&pio {
       gpio_i2c_0_scl {
               gpio_i2c_0_scl_default: gpio_i2c_0_scl_default {
                       GPIO_CONFIG_PUD_DRV(AP,pio,156, FUNC_INPUT, PULL_NONE, DRV_LV1);
               };
       };
};

/ {
	fragment@model {
		target-path = "/";
	        __overlay__ {
			aliases {
				  i2c30 = "/i2c@30";
			};
			/* Software I2C */
			sw_i2c0: i2c@30 {
				cell-index = <30>;
				compatible = "i2c-gpio";
				gpios = <
					SEC_GPIO_REF(AP,pio,157) 0 /* SDA */
					SEC_GPIO_REF(AP,pio,156) 0 /* SCL */
					>;
				#i2c-gpio,delay-us = <2>;
				#address-cells = <1>;
				#size-cells = <0>;

				pinctrl-names = "default";
				pinctrl-0 = <
					&gpio_i2c_0_sda_default
					&gpio_i2c_0_scl_default
					>;

				status = "disabled";
			};
		};
	};
};


/* #include "../sm5451_charger.dtsi" */              /* From sm5451_charger.py */
&i2c10 {
	status = "okay";

	sm5451_charger: sm5451@63 {
		compatible = "siliconmitus,sm5451";
		reg = <0x63>;
	};
};

/* #include "../sec_thermistor-2.dtsi" */            /* From sec_thermistor.py */
/ {
	fragment@smd {
		target-path = "/";
		__overlay__ {
			samsung_mobile_device {
				sec_cp_thermistor: sec_thermistor@2 {
					compatible = "samsung,sec-thermistor";
					status = "okay";
					thermistor_name = "sec-cp-thermistor";
					id = <2>;

					io-channels = SEC_ADC(auxadc,2);
					io-channel-names = "cp_therm";
					io-channel-ranges;
				};
			};
		};
	};
};

/* #include "../sec_thermistor.dtsi" */              /* From sec_thermistor.py */
/ {
	fragment@smd {
		target-path = "/";
		__overlay__ {
			samsung_mobile_device {
				sec_ap_thermistor: sec_thermistor@0 {
					compatible = "samsung,sec-thermistor";
					status = "okay";
					thermistor_name = "sec-ap-thermistor";
					id = <0>;

					io-channels = SEC_ADC(auxadc,0);
					io-channel-names = "ap_therm";
					io-channel-ranges;
				};
			};
		};
	};
};

/* #include "../sec_thermistor-1.dtsi" */            /* From sec_thermistor.py */
/ {
	fragment@smd {
		target-path = "/";
		__overlay__ {
			samsung_mobile_device {
				sec_pa_thermistor: sec_thermistor@1 {
					compatible = "samsung,sec-thermistor";
					status = "okay";
					thermistor_name = "sec-pa-thermistor";
					id = <1>;

					io-channels = SEC_ADC(auxadc,1);
					io-channel-names = "pa_therm";
					io-channel-ranges;
				};
			};
		};
	};
};

/* #include "../sec_thermistor-3.dtsi" */            /* From sec_thermistor.py */
/ {
	fragment@smd {
		target-path = "/";
		__overlay__ {
			samsung_mobile_device {
				sec_wf_thermistor: sec_thermistor@3 {
					compatible = "samsung,sec-thermistor";
					status = "okay";
					thermistor_name = "sec-wf-thermistor";
					id = <3>;

					io-channels = SEC_ADC(auxadc,4);
					io-channel-names = "wf_therm";
					io-channel-ranges;
				};
			};
		};
	};
};

/* /home/dpi/qb5_8814/workspace/P4_1716/android/kernel/kmodule/sec_pm/sec_thermistor/dts/sec_thermistor_mtk.m53x.dtsi */
&sec_ap_thermistor {
	adc_array = <81 98 121 146 177 214 258 312 379 457
				551 684 843 1021 1214 1440 1705 1994 2259 2593
				2919 3245 3579>;

	temp_array = <900 850 800 750 700 650 600 550 500 450
				400 350 300 250 200 150 100 50 0 (-50)
				(-100) (-150) (-200)>;
};

&sec_pa_thermistor {
	adc_array = <317 375 451 531 632 752 885 1033 1218 1410
				1630 1906 2211 2492 2765 3043 3321 3579 3782 4004>;

	temp_array = <900 850 800 750 700 650 600 550 500 450
				400 350 300 250 200 150 100 50 0 (-50)>;
};

&sec_cp_thermistor {
	adc_array = <318 376 451 531 632 752 885 1034 1217 1410
				1628 1905 2215 2490 2763 3043 3319 3578 3782 4004>;

	temp_array = <900 850 800 750 700 650 600 550 500 450
				400 350 300 250 200 150 100 50 0 (-50)>;
};

&sec_wf_thermistor {
	adc_array = <314 372 448 528 629 748 881 1029 1212 1405
				1623 1899 2207 2484 2757 3037 3314 3573 3777 4000>;

	temp_array = <900 850 800 750 700 650 600 550 500 450
				400 350 300 250 200 150 100 50 0 (-50)>;
};

/* #include "../fingerprint_et5xx.dtsi" */           /* From fingerprint_et5xx.py */
/*
 * Copyright (c) 2012-2013, The Linux Foundation. All rights reserved.
 *
 * This program is free software; you can redistribute it and/or modify
 * it under the terms of the GNU General Public License version 2 and
 * only version 2 as published by the Free Software Foundation.
 *
 * This program is distributed in the hope that it will be useful,
 * but WITHOUT ANY WARRANTY; without even the implied warranty of
 * MERCHANTABILITY or FITNESS FOR A PARTICULAR PURPOSE.  See the
 * GNU General Public License for more details.
 */

/* drive-strength */
&pio {
	btp_irq: btp-irq {
		pins_cmd_dat{
			pinmux = <MTK_PINMUX(SEC_GPIO_NUM(AP,pio,15), 0)>;
			bias-disable;
			drive-strength = <1>;
		};
	};
	btp_irq_sleep: btp-irq-sleep {
		pins_cmd_dat{
			pinmux = <MTK_PINMUX(SEC_GPIO_NUM(AP,pio,15), 0)>;
			bias-pull-down;
			input-enable;
			drive-strength = <1>;
		};
	};
};
#if 1
&pio {
	btp_ldo_en: btp_ldo_enable {
		pins_cmd_dat{
			pinmux = <MTK_PINMUX(SEC_GPIO_NUM(AP,pio,96), 0)>;
			bias-pull-down;
			drive-strength = <1>;
		};
	};
};
#endif

&pio {
	btp_sleep: btp_sleep_enable {
		pins_cmd_dat{
			pinmux = <MTK_PINMUX(SEC_GPIO_NUM(AP,pio,121), 0)>;
			bias-pull-down;
			drive-strength = <1>;
		};
	};
};

&pio {
	spi5_set_miso: set_miso {
		pins_cmd_dat{
			pinmux = <MTK_PINMUX(SEC_GPIO_NUM(AP,pio,100), 1)>;
			drive-strength = <4>;
		};
	};
	spi5_set_cs: set_cs {
		pins_cmd_dat{
			pinmux = <MTK_PINMUX(SEC_GPIO_NUM(AP,pio,99), 1)>;
			drive-strength = <4>;
		};
	};
	spi5_set_mosi: set_mosi {
		pins_cmd_dat{
			pinmux = <MTK_PINMUX(SEC_GPIO_NUM(AP,pio,101), 1)>;
			drive-strength = <4>;
		};
	};
	spi5_set_clk: set_clk {
		pins_cmd_dat{
			pinmux = <MTK_PINMUX(SEC_GPIO_NUM(AP,pio,98), 1)>;
			drive-strength = <4>;
		};
	};
	spi5_clr_miso: clr_miso {
		pins_cmd_dat{
			pinmux = <MTK_PINMUX(SEC_GPIO_NUM(AP,pio,100), 0)>;
			slew-rate = <0>;
			bias-pull-down;
			input-enable;
			drive-strength = <1>;
		};
	};
	spi5_clr_cs: clr_cs {
		pins_cmd_dat{
			pinmux = <MTK_PINMUX(SEC_GPIO_NUM(AP,pio,99), 0)>;
			slew-rate = <0>;
			bias-pull-down;
			output-low;
			drive-strength = <1>;
		};
	};
	spi5_clr_mosi: clr_mosi {
		pins_cmd_dat{
			pinmux = <MTK_PINMUX(SEC_GPIO_NUM(AP,pio,101), 0)>;
			slew-rate = <0>;
			bias-pull-down;
			output-low;
			drive-strength = <1>;
		};
	};
	spi5_clr_clk: clr_clk {
		pins_cmd_dat{
			pinmux = <MTK_PINMUX(SEC_GPIO_NUM(AP,pio,98), 0)>;
			slew-rate = <0>;
			bias-pull-down;
			output-low;
			drive-strength = <1>;
		};
	};
};
#if 0
&${fps_regul_vdd_3p3} {
    regulator-name = "VDD_BTP_3P3";
    regulator-min-microvolt = <3300000>;
    regulator-max-microvolt = <3300000>;
};
#endif
#if defined(CONFIG_SEC_FACTORY) || !1
&spi5 {
	status = "okay";
#else
&smd {
#endif
	#address-cells = <1>;
	#size-cells = <0>;

	etspi-spi@0 {
		compatible = "etspi,et5xx";
		reg = <0x00>;
		spi-max-frequency = <25000000>;
#if !defined(CONFIG_SEC_FACTORY) && 1
		clocks = <&topckgen_clk CLK_TOP_MAINPLL_D5_D4>,
			<&topckgen_clk CLK_TOP_SPI_SEL>,
			<&infracfg_ao_clk CLK_IFRAO_SPI5>;
		clock-names = "parent-clk", "sel-clk", "spi-clk";
#endif
		pinctrl-names = "default", "pins_poweron", "pins_poweroff", "pins_poweron_tz", "pins_poweroff_tz";
#if 1
		pinctrl-0 = <&btp_sleep &btp_irq &btp_ldo_en>;
#else
		pinctrl-0 = <&btp_sleep &btp_irq>;
#endif
		pinctrl-1 = <&spi5_set_miso &spi5_set_cs &spi5_set_mosi &spi5_set_clk>;
		pinctrl-2 = <&btp_sleep &spi5_clr_miso &spi5_clr_cs &spi5_clr_mosi &spi5_clr_clk>;
		pinctrl-3 = <&btp_irq>;
		pinctrl-4 = <&btp_irq_sleep>;
		gpio-controller;
		#gpio-cells = <2>;
#if 1
		etspi-ldoPin = <SEC_GPIO_REF(AP,pio,96) 0>;
#endif
#if 0
		etspi-regulator = "VDD_BTP_3P3";
#endif
		etspi-sleepPin = <SEC_GPIO_REF(AP,pio,121) 0>;
		etspi-drdyPin = <SEC_GPIO_REF(AP,pio,15) 0>;
		etspi-chipid = "ET528";
		etspi-orient = <2>;
		controller-data {
			mediatek,tckdly = <1>;	/* It'll be used after tckdly patch */
		};
	};
};

/* #include "../pmic_MT6360.dtsi" */                 /* From pmic_MT6360.py */
#if 1800000 && 1800000
&mt_pmic_vfp_ldo_reg {
    regulator-min-microvolt = <1800000>;
    regulator-max-microvolt = <1800000>;
    
     
};
#endif

#if 1800000 && 1800000
&mt_pmic_vtp_ldo_reg {
    regulator-min-microvolt = <1800000>;
    regulator-max-microvolt = <1800000>;
    regulator-always-on;
     
};
#endif

#if 0 && 0
&mt_pmic_vmc_ldo_reg {
    regulator-min-microvolt = <0>;
    regulator-max-microvolt = <0>;
    
     
};
#endif

#if 0 && 0
&mt_pmic_vmch_ldo_reg {
    regulator-min-microvolt = <0>;
    regulator-max-microvolt = <0>;
    
     
};
#endif

#if 0 && 0
&mt_pmic_vdram2_ldo_reg {
    regulator-min-microvolt = <${mt_pmic_vdram2_ldo7_ldo_reg_Vmin}>;
    regulator-max-microvolt = <${mt_pmic_vdram2_ldo7_ldo_reg_Vmax}>;
    ${mt_pmic_vdram2_ldo7_ldo_reg_basic_properties}
    ${mt_pmic_vdram2_ldo7_ldo_reg_opt_properties}
};
#endif
/* #include "../pmic_MT6365.dtsi" */                 /* From pmic_MT6365.py */
#if 0 && 0
&mt_pmic_vaud18_ldo_reg {
    regulator-min-microvolt = <0>;
    regulator-max-microvolt = <0>;
    
     
};
#endif

#if 0 && 0
&mt_pmic_vsim1_ldo_reg {
    regulator-min-microvolt = <0>;
    regulator-max-microvolt = <0>;
    
     
};
#endif

#if 3300000 && 3300000
&mt_pmic_vibr_ldo_reg {
    regulator-min-microvolt = <3300000>;
    regulator-max-microvolt = <3300000>;
    
     
};
#endif

#if 0 && 0
&mt_pmic_vrf12_ldo_reg {
    regulator-min-microvolt = <0>;
    regulator-max-microvolt = <0>;
    
     
};
#endif

#if 0 && 0
&mt_pmic_vusb_ldo_reg {
    regulator-min-microvolt = <0>;
    regulator-max-microvolt = <0>;
    
     
};
#endif

#if 0 && 0
&mt_pmic_vsram_proc2_ldo_reg {
    regulator-min-microvolt = <0>;
    regulator-max-microvolt = <0>;
    
     
};
#endif

#if 0 && 0
&mt_pmic_vio18_ldo_reg {
    regulator-min-microvolt = <0>;
    regulator-max-microvolt = <0>;
    
     
};
#endif

#if 0 && 0
&mt_pmic_vcamio_ldo_reg {
    regulator-min-microvolt = <0>;
    regulator-max-microvolt = <0>;
    
     
};
#endif

#if 0 && 0
&mt_pmic_vcn18_ldo_reg {
    regulator-min-microvolt = <0>;
    regulator-max-microvolt = <0>;
    
     
};
#endif

#if 0 && 0
&mt_pmic_vfe28_ldo_reg {
    regulator-min-microvolt = <0>;
    regulator-max-microvolt = <0>;
    
     
};
#endif

#if 0 && 0
&mt_pmic_vcn13_ldo_reg {
    regulator-min-microvolt = <0>;
    regulator-max-microvolt = <0>;
    
     
};
#endif

#if 0 && 0
&mt_pmic_vcn33_1_bt_ldo_reg {
    regulator-min-microvolt = <0>;
    regulator-max-microvolt = <0>;
    
     
};
#endif

#if 0 && 0
&mt_pmic_vcn33_1_wifi_ldo_reg {
    regulator-min-microvolt = <0>;
    regulator-max-microvolt = <0>;
    
     
};
#endif

#if 0 && 0
&mt_pmic_vaux18_ldo_reg {
    regulator-min-microvolt = <0>;
    regulator-max-microvolt = <0>;
    
     
};
#endif

#if 0 && 0
&mt_pmic_vsram_others_ldo_reg {
    regulator-min-microvolt = <0>;
    regulator-max-microvolt = <0>;
    
     
};
#endif

#if 0 && 0
&mt_pmic_vefuse_ldo_reg {
    regulator-min-microvolt = <0>;
    regulator-max-microvolt = <0>;
    
     
};
#endif

#if 0 && 0
&mt_pmic_vxo22_ldo_reg {
    regulator-min-microvolt = <0>;
    regulator-max-microvolt = <0>;
    
     
};
#endif

#if 0 && 0
&mt_pmic_vrfck_ldo_reg {
    regulator-min-microvolt = <0>;
    regulator-max-microvolt = <0>;
    
     
};
#endif

#if 0 && 0
&mt_pmic_vbif28_ldo_reg {
    regulator-min-microvolt = <0>;
    regulator-max-microvolt = <0>;
    
     
};
#endif

#if 3300000 && 3300000
&mt_pmic_vio28_ldo_reg {
    regulator-min-microvolt = <3300000>;
    regulator-max-microvolt = <3300000>;
    
     
};
#endif

#if 0 && 0
&mt_pmic_vemc_ldo_reg {
    regulator-min-microvolt = <0>;
    regulator-max-microvolt = <0>;
    
     
};
#endif

#if 0 && 0
&mt_pmic_vcn33_2_bt_ldo_reg {
    regulator-min-microvolt = <0>;
    regulator-max-microvolt = <0>;
    
     
};
#endif

#if 0 && 0
&mt_pmic_vcn33_2_wifi_ldo_reg {
    regulator-min-microvolt = <0>;
    regulator-max-microvolt = <0>;
    
     
};
#endif

#if 0 && 0
&mt_pmic_va12_ldo_reg {
    regulator-min-microvolt = <0>;
    regulator-max-microvolt = <0>;
    
     
};
#endif

#if 0 && 0
&mt_pmic_va09_ldo_reg {
    regulator-min-microvolt = <0>;
    regulator-max-microvolt = <0>;
    
     
};
#endif

#if 0 && 0
&mt_pmic_vrf18_ldo_reg {
    regulator-min-microvolt = <0>;
    regulator-max-microvolt = <0>;
    
     
};
#endif

#if 0 && 0
&mt_pmic_vsram_md_ldo_reg {
    regulator-min-microvolt = <0>;
    regulator-max-microvolt = <0>;
    
     
};
#endif

#if 0 && 0
&mt_pmic_vufs_ldo_reg {
    regulator-min-microvolt = <0>;
    regulator-max-microvolt = <0>;
    
     
};
#endif

#if 0 && 0
&mt_pmic_vm18_ldo_reg {
    regulator-min-microvolt = <0>;
    regulator-max-microvolt = <0>;
    
     
};
#endif

#if 0 && 0
&mt_pmic_vbbck_ldo_reg {
    regulator-min-microvolt = <0>;
    regulator-max-microvolt = <0>;
    
     
};
#endif

#if 0 && 0
&mt_pmic_vsram_proc1_ldo_reg {
    regulator-min-microvolt = <0>;
    regulator-max-microvolt = <0>;
    
     
};
#endif

#if 0 && 0
&mt_pmic_vsim2_ldo_reg {
    regulator-min-microvolt = <0>;
    regulator-max-microvolt = <0>;
    
     
};
#endif

/* #include "../sensors_isg5320a.dtsi" */            /* From sensors_isg5320a.py */
#if 1

&i2c7 {
	#address-cells = <1>;
	#size-cells = <0>;
	status = "okay";
	clock-frequency = <400000>;
	pinctrl-names = "default";
#if 1
	pinctrl-0 = <&grip_ldo_en>;
#endif

	isg5320a: isg5320a-i2c@2C {
		compatible = "isg5320a";
		status = "okay";
		reg = <0x2C>;
		pinctrl-names = "default";
		pinctrl-0 = <&grip_int>;

		interrupt-parent = <SEC_GPIO_TYPE(AP,pio,17)>;
		interrupts = <SEC_GPIO_NUM(AP,pio,17) 0>;

		isg5320a,irq-gpio = <SEC_GPIO_REF(AP,pio,17) 0>;
		isg5320a,hallic_detect = <1>;
		isg5320a,hallic_cert_detect = <1>;

		isg5320a,reg_num = <150>;
	};
};

&pio {
	grip_int: grip-int {
		pins_cmd_dat {
			pinmux = <MTK_PINMUX(SEC_GPIO_NUM(AP,pio,17), 0)>;
			slew-rate = <0>;
			bias-disable;
		};
	};
};

#if 1
&pio {
	grip_ldo_en: grip-ldo-en {
		pins_cmd_dat {
			pinmux = <MTK_PINMUX(SEC_GPIO_NUM(AP,pio,110), 0)>;
			slew-rate = <1>;
			bias-disable;
			output-high;
		};
	};
};
#endif

#if 0
&pio {
	grip_i2c: grip-i2c {
		pins_cmd0_dat {
			pinmux = <MTK_PINMUX(SEC_GPIO_NUM(AP,pio,135), 0)>;
			slew-rate = <0>;
			bias-disable;
		};
		pins_cmd1_dat {
			pinmux = <MTK_PINMUX(SEC_GPIO_NUM(AP,pio,134), 0)>;
			slew-rate = <0>;
			bias-disable;
		};
	};
};
#endif
#endif /*isg5320a*/



#if 1

&i2c7 {
	#address-cells = <1>;
	#size-cells = <0>;
	status = "okay";
	clock-frequency = <400000>;
	pinctrl-names = "default";
#if 0
	pinctrl-0 = <&grip_sub_ldo_en>;
#endif
	isg5320a_sub: isg5320a-sub-i2c@28 {
		compatible = "isg5320a_sub";
		status = "okay";
		reg = <0x28>;
		pinctrl-names = "default";
		pinctrl-0 = <&grip_sub_int>;

		interrupt-parent = <SEC_GPIO_TYPE(AP,pio,0)>;
		interrupts = <SEC_GPIO_NUM(AP,pio,0) 0>;

		isg5320a_sub,irq-gpio = <SEC_GPIO_REF(AP,pio,0) 0>;
		isg5320a_sub,hallic_detect = <1>;
		isg5320a_sub,hallic_cert_detect = <1>;

		isg5320a_sub,reg_num = <150>;
	};
};

&pio {
	grip_sub_int: grip-sub-int {
		pins_cmd_dat {
			pinmux = <MTK_PINMUX(SEC_GPIO_NUM(AP,pio,0), 0)>;
			slew-rate = <0>;
			bias-disable;
		};
	};
};

#if 0
&pio {
	grip_sub_ldo_en: grip-sub-ldo-en {
		pins_cmd_dat {
			pinmux = <MTK_PINMUX(SEC_GPIO_NUM(${gpio_grip_sub_en}), 0)>;
			slew-rate = <1>;
			bias-disable;
			output-high;
		};
	};
};
#endif

#if 0
&pio {
	grip_sub_i2c: grip-sub-i2c {
		pins_cmd0_dat {
			pinmux = <MTK_PINMUX(SEC_GPIO_NUM(AP,pio,135), 0)>;
			slew-rate = <0>;
			bias-disable;
		};
		pins_cmd1_dat {
			pinmux = <MTK_PINMUX(SEC_GPIO_NUM(AP,pio,134), 0)>;
			slew-rate = <0>;
			bias-disable;
		};
	};
};
#endif

#endif /*isg5320a_sub*/

/* /home/dpi/qb5_8814/workspace/P4_1716/android/kernel/kmodule/sensors/isg5320a/dts/isg5320a_mtk.m53x.dtsi */
&pio {
	grip_i2c: grip-i2c {
		pins_cmd0_dat {
			bias-pull-up;
			pinmux = <0x8701>;
			input-enable;
			drive-strength = <0x4>;
		};
		pins_cmd1_dat {
			pinmux = <0x8601>;
			bias-pull-up;
			input-enable;
			drive-strength = <0x4>;
		};
	};
};

&i2c7 {
	pinctrl-0 = <&grip_ldo_en &grip_i2c>;
};

&isg5320a {
	isg5320a,set_reg = /bits/ 8 <
		0x05 0xFC
		0x06 0xF1
		0x07 0x13
		0x08 0x01
		0x09 0x80
		0x0A 0x20
		0x0B 0x00
		0x0C 0x00
		0x12 0x89
		0x19 0x8A
		0x1B 0x28
		0x1D 0x20
		0x1E 0x00
		0x1F 0x18
		0x20 0x05
		0x21 0x10
		0x22 0x10
		0x23 0x00
		0x24 0x00
		0x25 0x05
		0x26 0x05
		0x27 0x10
		0x28 0x20
		0x29 0x00
		0x2A 0x20
		0x2B 0x00
		0x2C 0x00
		0x2D 0x20
		0x2F 0x18
		0x30 0xC0
		0x41 0x11
		0x60 0xF0
		0x61 0x8F
		0x62 0x07
		0x63 0x00
		0x64 0x00
		0x65 0x44
		0x66 0x3C
		0x67 0x01
		0x68 0x00
		0x69 0x00
		0x6A 0x10
		0x6B 0x00
		0x6C 0x10
		0x6D 0x40
		0x6E 0x22
		0x6F 0x00
		0x70 0x01
		0x71 0x60
		0x72 0xFF
		0x73 0xFF
		0x74 0xFF
		0x7B 0x08
		0x7C 0x00
		0x7D 0x0C
		0x7E 0x00
		0x7F 0xF8
		0x80 0xF8
		0x81 0x00
		0x82 0xF0
		0x83 0xF0
		0x84 0xF0
		0x85 0xF0
		0x86 0xF0
		0x87 0xF0
		0x88 0x00
		0x89 0x00
		0x8A 0x08
		0x8B 0x00
		0x8C 0x02
		0x8D 0x00
		0x99 0x21
		0x9A 0x3C
		0x9B 0x01
		0x9C 0x5E
		0x9D 0x00
		0x9E 0x00
		0x9F 0x00
		0xA0 0xC8
		0xA1 0xC0
		0xA2 0x22
		0xA3 0x00
		0xA4 0x08
		0xA5 0x60
		0xA6 0xFF
		0xA7 0xFF
		0xA8 0xFF
		0xA9 0x00
		0xAF 0x40
		0xB0 0x00
		0xB1 0x60
		0xB2 0x00
		0xB3 0xE0
		0xB4 0x70
		0xB5 0x28
		0xB6 0xFD
		0xB7 0x40
		0xB8 0xFD
		0xB9 0xFB
		0xBA 0xF0
		0xBB 0xF0
		0xBC 0x00
		0xBD 0x00
		0xBE 0x0B
		0xBF 0xB8
		0xC0 0x00
		0xC1 0x78
		0xC2 0xF0
		0xC3 0x00
		0xC4 0x00
		0xC5 0x00
		0x13 0x3A
		0x18 0xF1
		0x1C 0x18
		0x35 0x00
		0x36 0x00
		0x3A 0x08
		0x3B 0x50
		0x3C 0x08
		0x3D 0x50
		0x3E 0x60
		0x94 0x10
		0x95 0xA8
		0x96 0x03
		0x2E 0x15
		0x0E 0xE0
		0x0F 0x1C
		0x10 0xC0
		0x11 0xC1
		0xD0 0xE0
		0xD1 0x02
		0xD2 0x00
		0xD3 0xFF
		0xD4 0xFF
		0xD5 0x10
		0xD6 0x46
		0xD7 0xFF
		0xD8 0x1E
		0xD9 0x80
		0xDA 0x81
		0xDB 0xB0
		0xDC 0x00
		0x76 0x08
		0x77 0x00
		0x79 0x02
		0x7A 0x00
		0xAA 0x32
		0xAB 0xC8
		0xAD 0x04
		0xAE 0x00
		>;
};

&isg5320a_sub {
	isg5320a_sub,set_reg = /bits/ 8 <
		0x05 0xFC
		0x06 0xF1
		0x07 0x13
		0x08 0x01
		0x09 0x80
		0x0A 0x20
		0x0B 0x00
		0x0C 0x00
		0x12 0x89
		0x19 0x8A
		0x1B 0x1D
		0x1D 0x19
		0x1E 0x00
		0x1F 0x14
		0x20 0x05
		0x21 0x10
		0x22 0x10
		0x23 0x00
		0x24 0x00
		0x25 0x05
		0x26 0x05
		0x27 0x10
		0x28 0x19
		0x29 0x00
		0x2A 0x19
		0x2B 0x00
		0x2C 0x00
		0x2D 0x19
		0x2F 0x18
		0x30 0xC0
		0x41 0x11
		0x60 0xF0
		0x61 0x8F
		0x62 0x0B
		0x63 0x00
		0x64 0x00
		0x65 0x44
		0x66 0x3C
		0x67 0x01
		0x68 0x00
		0x69 0x00
		0x6A 0x10
		0x6B 0x00
		0x6C 0x10
		0x6D 0x40
		0x6E 0x22
		0x6F 0x00
		0x70 0x01
		0x71 0x60
		0x72 0xFF
		0x73 0xFF
		0x74 0xFF
		0x7B 0x08
		0x7C 0x00
		0x7D 0x0C
		0x7E 0x00
		0x7F 0xF8
		0x80 0xF8
		0x81 0x00
		0x82 0xF0
		0x83 0xF0
		0x84 0xF0
		0x85 0xF0
		0x86 0xF0
		0x87 0xF0
		0x88 0x00
		0x89 0x00
		0x8A 0x08
		0x8B 0x00
		0x8C 0x02
		0x8D 0x00
		0x99 0x21
		0x9A 0x3C
		0x9B 0x01
		0x9C 0x5E
		0x9D 0x00
		0x9E 0x00
		0x9F 0x00
		0xA0 0xC8
		0xA1 0xC0
		0xA2 0x22
		0xA3 0x00
		0xA4 0x08
		0xA5 0x60
		0xA6 0xFF
		0xA7 0xFF
		0xA8 0xFF
		0xA9 0x00
		0xAF 0x40
		0xB0 0x00
		0xB1 0x60
		0xB2 0x00
		0xB3 0xE0
		0xB4 0x60
		0xB5 0x28
		0xB6 0xFD
		0xB7 0x40
		0xB8 0xFD
		0xB9 0xA0
		0xBA 0xF0
		0xBB 0xF0
		0xBC 0x00
		0xBD 0x00
		0xBE 0x01
		0xBF 0x00
		0xC0 0x00
		0xC1 0x78
		0xC2 0xF0
		0xC3 0x00
		0xC4 0x00
		0xC5 0x00
		0x13 0x3A
		0x18 0xF1
		0x1C 0x18
		0x35 0x00
		0x36 0x00
		0x3A 0x08
		0x3B 0x50
		0x3C 0x08
		0x3D 0x50
		0x3E 0x60
		0x94 0xF0
		0x95 0xBA
		0x96 0x02
		0x2E 0x17
		0x0E 0xE0
		0x0F 0x9C
		0x10 0x40
		0x11 0xC1
		0xD0 0xE0
		0xD1 0x02
		0xD2 0x00
		0xD3 0xFF
		0xD4 0xFF
		0xD5 0x10
		0xD6 0x46
		0xD7 0xFF
		0xD8 0x1E
		0xD9 0x80
		0xDA 0x81
		0xDB 0xB0
		0xDC 0x00
		0x76 0x08
		0x77 0x00
		0x79 0x02
		0x7A 0x00
		0xAA 0x32
		0xAB 0xC8
		0xAD 0x04
		0xAE 0x00
		>;
};

/* #include "../sensorhub_mt6877_shub.dtsi" */       /* From sensorhub_mt6877_shub.py */
/ {
	fragment@model {
		target-path = "/";
		__overlay__ {
			shub {
				compatible = "shub";
			};
		};
	};
};

/* /home/dpi/qb5_8814/workspace/P4_1716/android/kernel/kmodule/sensorhub/mtk/mt6877_shub/dts/sensorhub_mt6877_shub.m53x.dtsi */
/ {
	fragment@model {
		target-path = "/";
		__overlay__ {
			shub {
				acc-motor-coef = <5>;
				acc-lsm6dsl-position = <3>;
				
				mag-mmc5633-position = <3>;
				mag-check-nfc = <&pio 90 0>;
				mag-mmc5633-array = /bits/ 8 <39 93 1 23 1 40 0 61 38
							215 0 201 255 90 255 181 40 238
							0 0 0 0 0 0 0 0 0>;
				mag-mmc5633-nfc-array = /bits/ 8 <39 76 3 212 0 70 3 212 36
							34 255 156 0 70 255 156 41 194
							0 0 0 0 0 0 0 0 0>;

				light-position = /bits/ 32 <45 8 6 2 2 8>;
			};
		};
	};
};

/* /home/dpi/qb5_8814/workspace/P4_1716/android/kernel/kmodule/sensorhub/mtk/mt6877_shub/dts/sensorhub_mt6877_shub.m53x.04.dtsi */
/ {
	fragment@model {
		target-path = "/";
		__overlay__ {
			shub {
				mag-mmc5633-nfc-array = /bits/ 8 <38 45 3 148 1 65 3 51 36
								246 255 178 255 120 255 215 41 139
								0 0 0 0 0 0 0 0 0>;
			};
		};
	};
};

/* #include "../regulator-fixed.dtsi" */             /* From regulator-fixed.py */
/* 
 * This pinctrl code is only for PULL state change.
 * IN-OUT setting is set to OUTPUT at fixed-regulator probe.
 */

&pio {
        ldo_gpio0: ldo_gpio0 {
                GPIO_CONFIG_PUD(AP,pio,18, FUNC_OUTPUT_HIGH, PULL_NONE);
#if 0
		samsung,pin-con-pdn = <3>;
		samsung,pin-pud-pdn = <0>;
#endif
        };
};

&smd {
	fixed_regulator0: fixed_regulator@0 {
		compatible = "regulator-fixed";
#if 0
		regulator-name = "${fixed_regulator_name}";
#else
		regulator-name = "fixed_regulator0";
#endif
		gpio = <SEC_GPIO_REF(AP,pio,18) 0>;
		pinctrl-names = "default";
		pinctrl-0 = <&ldo_gpio0>;
		enable-active-high;
	};
};


/* #include "../nfc_stm.dtsi" */                     /* From nfc_stm.py */
/*
 * This program is free software; you can redistribute it and/or modify
 * it under the terms of the GNU General Public License version 2 and
 * only version 2 as published by the Free Software Foundation.
 *
 * This program is distributed in the hope that it will be useful,
 * but WITHOUT ANY WARRANTY; without even the implied warranty of
 * MERCHANTABILITY or FITNESS FOR A PARTICULAR PURPOSE.  See the
 * GNU General Public License for more details.
 */
#include <dt-bindings/pinctrl/mt6877-pinfunc.h>
&pio {
	nfc_rst: nfc_rst {
		pins_cmd_dat {
			pinmux = <MTK_PINMUX(SEC_GPIO_NUM(AP,pio,107), 0)>;
			output-low;
			bias-disable;
		};
	};
	nfc_rst_nc: nfc_rst_nc {
		pins_cmd_dat {
			pinmux = <MTK_PINMUX(SEC_GPIO_NUM(AP,pio,107), 0)>;
			output-low;
			bias-pull-down;
		};
	};
};
&pio {
	nfc_clk_req: nfc_clk_req {
		pins_cmd_dat{
			pinmux =  <MTK_PINMUX(SEC_GPIO_NUM(AP,pio,13), 0)>;
			input-enable;
			bias-disable;
		};
	};
	clk_req_nc: clk_req_nc {
		pins_cmd_dat{
			pinmux =  <MTK_PINMUX(SEC_GPIO_NUM(AP,pio,13), 0)>;
			input-enable;
			bias-pull-down;
		};
	};
};

&pio {
	nfc_irq: nfc_irq {
		pins_cmd_dat {
			pinmux = <MTK_PINMUX(SEC_GPIO_NUM(AP,pio,11), 0)>;
			input-enable;
			bias-pull-down;
		};
	};

	irq_nc: irq_nc {
		pins_cmd_dat {
			pinmux = <MTK_PINMUX(SEC_GPIO_NUM(AP,pio,11), 0)>;
			input-enable;
			bias-pull-down;
		};
	};
};

&pio {
	nfc_i2c_off: nfc_i2c_off {
		pins_cmd_dat {
			pinmux = <MTK_PINMUX(SEC_GPIO_NUM(AP,pio,186), 0)>,
				<MTK_PINMUX(SEC_GPIO_NUM(AP,pio,187), 0)>;
			input-enable;
			bias-pull-down;
		};
	};
	nfc_i2c_on: nfc_i2c_on {
		pins_cmd_dat {
			pinmux = <MTK_PINMUX(SEC_GPIO_NUM(AP,pio,186), 1)>,
				<MTK_PINMUX(SEC_GPIO_NUM(AP,pio,187), 1)>;
			input-enable;
			bias-pull-up;
		};
	};
};

#if 1
&pio {
	nfc_check: nfc_check {
		pins_cmd_dat {
			pinmux = <MTK_PINMUX(SEC_GPIO_NUM(AP,pio,90), 0)>;
			input-enable;
			bias-disable;
		};
	};
};
#endif

&i2c3 {
	status = "ok";
	#address-cells = <1>;
	#size-cells = <0>;
	clock-frequency = <400000>;
	mediatek,use-open-drain;

	st21nfc: st21nfc@08 {
		compatible = "st,st21nfc";
		reg = <0x08>;
		interrupt-parent = <&pio>;
		interrupts = <SEC_GPIO_NUM(AP,pio,11) IRQ_TYPE_EDGE_RISING
			SEC_GPIO_NUM(AP,pio,11) 0>;
		irq-gpios = <SEC_GPIO_REF(AP,pio,11) 0>;
		reset-gpios = <SEC_GPIO_REF(AP,pio,107) 0>;
		/*pidle-gpios = <&tlmm 48 0x00>;*/
		clkreq-gpios = <SEC_GPIO_REF(AP,pio,13) 0>;
		st21nfc,ap_vendor = "mtk";
#if 1
		st21nfc,nfc-det-gpio = <SEC_GPIO_REF(AP,pio,90) 0>;
#endif
#if 0
		st21nfc,late_pvdd_en;
#endif
#if 1
		st21nfc,clk_req_wake;
#endif
#if 1
		nfc_pvdd-supply = <&mt_pmic_vfp_ldo_reg>;
#endif
		pinctrl-names = "default", "nfc_nc", "nfc_on", "i2c_off";
		pinctrl-0 = <&nfc_clk_req &nfc_irq &nfc_i2c_off &nfc_rst
#if 1
			&nfc_check
#endif
			>;
		pinctrl-1 = <&clk_req_nc &irq_nc &nfc_rst_nc>;
		pinctrl-2 = <&nfc_i2c_on>;
		pinctrl-3 = <&nfc_i2c_off>;

	};
};

&mt_pmic_vfp_ldo_reg {
	regulator-name = "nfc_pvdd";
};


/* #include "../dc_vibrator.dtsi" */                 /* From dc_vibrator.py */
/ {
	fragment@smd {
		target-path = "/";
			__overlay__ {
				samsung_mobile_device {
					dc_vibrator {
						compatible = "samsung,dc_vibrator";
						status = "okay";
						dc_vib,motor_type = "COINDC";
#if 1
						dc_vib,regulator_name = "dc_vib";
						dc_vib-supply = <&mt_pmic_vibr_ldo_reg>;
#endif
					};
				};
			};
	};
};

/* #include "../s2mpb03.dtsi" */                     /* From s2mpb03.py */
&sw_i2c0 {
	#address-cells = <1>;
	#size-cells = <0>;
	status = "okay";
	s2mpb03_pmic_0: s2mpb03_pmic@56 {
		compatible = "samsung,s2mpb03pmic";
		reg = <0x56>;
		s2mpb03,wakeup;

		regulators {
			s2mpb03_0_l1: s2mpb03-ldo1 {
				regulator-name = "CAM0_s2mpb03-l1";
				regulator-min-microvolt = <1050000>;
				regulator-max-microvolt = <1050000>;
				
				 
			};

			s2mpb03_0_l2: s2mpb03-ldo2 {
				regulator-name = "CAM0_s2mpb03-l2";
				regulator-min-microvolt = <1200000>;
				regulator-max-microvolt = <1200000>;
				
				 
			};

			s2mpb03_0_l3: s2mpb03-ldo3 {
				regulator-name = "CAM0_s2mpb03-l3";
				regulator-min-microvolt = <1800000>;
				regulator-max-microvolt = <1800000>;
				
				 
			};

			s2mpb03_0_l4: s2mpb03-ldo4 {
				regulator-name = "CAM0_s2mpb03-l4";
				regulator-min-microvolt = <1200000>;
				regulator-max-microvolt = <1200000>;
				
				 
			};

			s2mpb03_0_l5: s2mpb03-ldo5 {
				regulator-name = "CAM0_s2mpb03-l5";
				regulator-min-microvolt = <2200000>;
				regulator-max-microvolt = <2200000>;
				
				 
			};

			s2mpb03_0_l6: s2mpb03-ldo6 {
				regulator-name = "CAM0_s2mpb03-l6";
				regulator-min-microvolt = <2900000>;
				regulator-max-microvolt = <2900000>;
				
				 
			};

			s2mpb03_0_l7: s2mpb03-ldo7 {
				regulator-name = "CAM0_s2mpb03-l7";
				regulator-min-microvolt = <2800000>;
				regulator-max-microvolt = <2800000>;
				
				 
			};
		};
	};
};

/* #include "../sec_direct_charger.dtsi" */          /* From sec_direct_charger.py */

&smd {
	sec-direct-charger {
		status = "okay";
		compatible = "samsung,sec-direct-charger";

		charger,battery_name = "battery";
		charger,main_charger = "mtk-charger";
		charger,direct_charger = "sm5451-charger";

		charger,dchg_min_current = <2000>;

		charger,ta_alert_wa;
	};
};


/* #include "../sensorhub_shub.dtsi" */              /* From sensorhub_shub.py */
#if 1
&mt_pmic_vtp_ldo_reg {
	regulator-name = "VDD_SENSOR_1P8";
};
#endif
#if 0
&${gpio_sensor_ldo_en_parent} {
	shub_sensor_ldo_en: shub-sensor-ldo-en {
		samsung,pins = SEC_GPIO(${gpio_sensor_ldo_en});
		samsung,pin-function = <1>;
		samsung,pin-pud = <0>;
		samsung,pin-con-pdn = <3>;
		samsung,pin-pud-pdn = <0>;
	};
};
#endif
/ {
	fragment@model {
		target-path = "/";
		__overlay__ {
			shub {
#if 0
    			pinctrl-names = "default";
				pinctrl-0 = <&shub_sensor_ldo_en>;
#endif
#if 1
				sensor-vdd-regulator = "VDD_SENSOR_1P8";
#endif

#if 0
				mag-check-nfc = <SEC_GPIO_REF(${gpio_nfc_check}) 0>;
#endif

#if 0
				pogo-int = <SEC_GPIO_REF(${gpio_pogo_int}) 0>;
#endif

#if 0
				sensor-ldo-en = <SEC_GPIO_REF(${gpio_sensor_ldo_en}) 0>;
#endif
			};
		};
	};
};

/* #include "../input_synaptics.dtsi" */             /* From input_synaptics.py */
&pio {
	synaptics_attn_irq: synaptics_attn_irq {
		GPIO_CONFIG_PUD(AP,pio,14, FUNC_INPUT_WAKEUP, PULL_NONE);
	};

	synaptics_attn_input: synaptics_attn_input {
		GPIO_CONFIG_PUD(AP,pio,14, FUNC_INPUT, PULL_DOWN);
	};
};

&i2c0 {
	#address-cells = <1>;
	#size-cells = <0>;
	status = "ok";
	clock-frequency = <400000>;
	samsung,reset-before-trans;
	samsung,stop-after-trans;	/* LSI IC ONLY */
	tsp_synaptics: touchscreen@4b {
		status = "ok";
		compatible = "synaptics,synaptics_ts";
		reg = <0x4b>;
		pinctrl-names = "on_state", "off_state";
		pinctrl-0 = <&synaptics_attn_irq>;
		pinctrl-1 = <&synaptics_attn_input>;
		tsp_io_ldo-supply = <&fixed_regulator0>;
		tsp_avdd_ldo-supply = <&mt_pmic_vio28_ldo_reg>;
		sec,irq_gpio = <SEC_GPIO_REF(AP,pio,14) 0>;

		/* This part is for firmware */
		sec,project_name = "m53x", "m53x";
		sec,bringup = <0>;
	};
};


/* /home/dpi/qb5_8814/workspace/P4_1716/android/kernel/kmodule/input/sec_input/touchscreen/synaptics/dts/input-mtk-tsp-synaptics.m53x.dtsi */
&tsp_synaptics {
	tsp_io_ldo-supply = <&mt_pmic_vio28_ldo_reg>; /* avdd */ /* switch 3.3 ->1.8 for power on sequence */
	tsp_avdd_ldo-supply = <&fixed_regulator0>; /* dvdd */
	sec,area-size = <133 266 341>; /* indicator: 24dp navigator:48dp edge:60px dpi=320 */
	sec,max_coords = <4096 4096>; /* x y */
	enable_settings_aot;
	support_dex_mode;
	//support_mis_calibration_test;
	support_ear_detect_mode;
	//sync-reportrate-120;
	support_refresh_rate_mode;
	support_open_short_test;
	support_fod;
	support_fod_lp_mode;
	support_vrr;
	sec,lcdid_mask = <0xFF0000>;
	sec,select_lcdid = <0x800000 0x010000>;
	sec,firmware_name = "tsp_synaptics/s3908_m52xq_sdc.bin", "tsp_synaptics/s3908_m53x_boe.bin";
	sec,tclm_level = <0xFF>;
	sec,afe_base = <0x0000>;
	sec,i2c-burstmax = <4096>;
	sec,enable_sysinput_enabled;
};

/* #include "../battery_common.dtsi" */              /* From battery_common.py */
#include <dt-bindings/battery/sec-battery.h>

&smd {
	sec_battery: battery {
		status = "okay";
		compatible = "samsung,sec-battery";
		battery,vendor = "Battery";
		battery,charger_name = "sec-direct-charger";
		battery,fuelgauge_name = "mtk-fg-battery";
		battery,technology = <2>; /* POWER_SUPPLY_TECHNOLOGY_LION */
		battery,chip_vendor = "NONE";

		battery,batt_data_version = <1>;

		battery,adc_check_count = <5>;
		battery,temp_check_type = <SEC_BATTERY_TEMP_CHECK_NONE>;
		battery,usb_temp_check_type = <SEC_BATTERY_TEMP_CHECK_NONE>;
		battery,chg_temp_check_type = <SEC_BATTERY_TEMP_CHECK_NONE>;
		battery,wpc_temp_check_type = <SEC_BATTERY_TEMP_CHECK_NONE>;
		battery,lrp_temp_check_type = <SEC_BATTERY_TEMP_CHECK_NONE>;

		battery,thermal_source = <SEC_BATTERY_THERMAL_SOURCE_NONE>; /* SEC_BATTERY_THERMAL_SOURCE_NONE */
		battery,usb_thermal_source = <SEC_BATTERY_THERMAL_SOURCE_NONE>; /* SEC_BATTERY_THERMAL_SOURCE_NONE */
		battery,chg_thermal_source = <SEC_BATTERY_THERMAL_SOURCE_NONE>; /* SEC_BATTERY_THERMAL_SOURCE_NONE */
		battery,wpc_thermal_source = <SEC_BATTERY_THERMAL_SOURCE_NONE>; /* SEC_BATTERY_THERMAL_SOURCE_NONE */

		battery,inbat_ocv_type =  <SEC_BATTERY_OCV_NONE>;

		battery,polling_time = <10 30 30 30 3600>;

		battery,cable_check_type = <SEC_BATTERY_CABLE_CHECK_PSY>;
		battery,cable_source_type = <SEC_BATTERY_CABLE_SOURCE_EXTERNAL>;
		battery,polling_type = <SEC_BATTERY_MONITOR_ALARM>; /* SEC_BATTERY_MONITOR_ALARM */
		battery,monitor_initial_count = <0>;

		battery,battery_check_type = <0>; /* SEC_BATTERY_CHECK_NONE */

		battery,ovp_uvlo_check_type = <SEC_BATTERY_OVP_UVLO_CHGPOLLING>; /* SEC_BATTERY_OVP_UVLO_CHGPOLLING */

		battery,temp_check_count = <1>;

		battery,usb_protection_temp = <610>;
		battery,temp_gap_bat_usb = <200>;
		battery,overheatlimit_threshold = <700>;
		battery,overheatlimit_recovery = <680>;
		battery,wire_warm_overheat_thresh = <500>;
		battery,wire_normal_warm_thresh = <420>;
		battery,wire_cool1_normal_thresh = <180>;
		battery,wire_cool2_cool1_thresh = <150>;
		battery,wire_cool3_cool2_thresh = <50>;
		battery,wire_cold_cool3_thresh = <0>;
		battery,wireless_warm_overheat_thresh = <500>;
		battery,wireless_normal_warm_thresh = <420>;
		battery,wireless_cool1_normal_thresh = <180>;
		battery,wireless_cool2_cool1_thresh = <150>;
		battery,wireless_cool3_cool2_thresh = <50>;
		battery,wireless_cold_cool3_thresh = <0>;
		battery,tx_high_threshold = <500>;
		battery,tx_high_recovery = <450>;
		battery,tx_low_threshold = <0>;
		battery,tx_low_recovery = <50>;

		battery,wire_warm_current = <1573>;	/* 0.36C */
		battery,wire_cool1_current = <3146>;	/* 0.72C */
		battery,wire_cool2_current = <1048>;	/* 0.24C */
		battery,wire_cool3_current = <437>;	/* 0.1C */
		battery,wireless_warm_current = <1048>;		/* 0.24C */
		battery,wireless_cool1_current = <3146>;	/* 0.72C */
		battery,wireless_cool2_current = <1048>;	/* 0.24C */
		battery,wireless_cool3_current = <437>;		/* 0.1C */

		battery,full_check_type = <SEC_BATTERY_FULLCHARGED_CHGPSY>;
		battery,full_check_type_2nd = <SEC_BATTERY_FULLCHARGED_CHGPSY>;
		battery,full_check_count = <1>;
		battery,chg_gpio_full_check = <0>;
		battery,chg_polarity_full_check = <1>;

		battery,chg_high_temp = <470>;
		battery,chg_high_temp_recovery = <450>;
		battery,chg_input_limit_current = <1000>;
		battery,chg_charging_limit_current = <1900>;

		battery,dchg_high_temp = <520>;
		battery,dchg_high_temp_recovery = <460>;
		battery,dchg_high_batt_temp = <400>;
		battery,dchg_high_batt_temp_recovery = <380>;
		battery,dchg_input_limit_current = <1000>;
		battery,dchg_charging_limit_current = <2000>;

		battery,wpc_temp_control_source = <TEMP_CONTROL_SOURCE_BAT_THM>;
		battery,wpc_high_temp = <400>;
		battery,wpc_high_temp_recovery = <380>;
		battery,wpc_input_limit_current = <800>;
		battery,wpc_charging_limit_current = <1000>;
		battery,wpc_temp_lcd_on_control_source = <TEMP_CONTROL_SOURCE_BAT_THM>;
		battery,wpc_lcd_on_input_limit_current = <800>;

		battery,wpc_store_high_temp = <360>;
		battery,wpc_store_high_temp_recovery = <340>;
		battery,wpc_store_charging_limit_current = <400>;
		battery,wpc_store_lcd_on_high_temp = <360>;
		battery,wpc_store_lcd_on_high_temp_rec = <300>;
		battery,wpc_store_lcd_on_charging_limit_current = <400>;

		battery,fcc_by_tx = <1200>;

		battery,sleep_mode_limit_current = <800>;
		battery,wc_full_input_limit_current = <100>;

		battery,ta_alert_wa;

		battery,mix_high_temp = <420>;
		battery,mix_high_chg_temp = <500>;
		battery,mix_high_temp_recovery = <390>;

		/* battery,usb_conn_slope_avg = <9>; */

		/* battery,enable_mix_v2; */
		/* if you want to use mix_v2 concept, add "battery,enable_mix_v2;" */
		battery,mix_v2_lrp_recov = <460>;
		battery,mix_v2_lrp_cond = <480>;
		battery,mix_v2_bat_cond = <480>;
		battery,mix_v2_chg_cond = <0>;	/* 0 means no use chg thm condition */
		battery,mix_v2_dchg_cond = <0>; /* 0 means no use dchg thm condition */

		battery,full_condition_type = <(SEC_BATTERY_FULL_CONDITION_NOTIMEFULL | SEC_BATTERY_FULL_CONDITION_VCELL)>;
		battery,full_condition_soc = <93>;
		battery,full_condition_vcell = <4250>;

		battery,recharge_check_count = <1>;
		battery,recharge_condition_type = <SEC_BATTERY_RECHARGE_CONDITION_VCELL>;
		battery,recharge_condition_soc = <98>;
		battery,recharge_condition_vcell = <4280>;

		battery,charging_reset_time = <0>;

		battery,chg_float_voltage = <4350>;

		battery,pre_afc_work_delay = <2000>;
		battery,pre_wc_afc_work_delay = <4000>;
		battery,pre_afc_input_current = <500>;
		battery,pre_wc_afc_input_current = <500>;

		battery,swelling_high_rechg_voltage = <4000>;
		battery,swelling_low_rechg_voltage = <4000>;

		battery,siop_icl = <1200>;
		battery,siop_fcc = <1800>;
		battery,siop_hv_icl = <700>;
		battery,siop_hv_icl_2nd = <550>;
		battery,siop_hv_fcc = <1800>;
		battery,siop_apdo_icl = <1000>;
		battery,siop_apdo_fcc = <2000>;

		battery,siop_wpc_icl = <600>;
		battery,siop_wpc_fcc = <1000 500 100>; /* siop_level 70 10 0 */
		battery,siop_hv_wpc_icl = <700>;
		battery,siop_hv_wpc_fcc = <1000 500 100>; /* siop_level 70 10 0 */
		battery,siop_store_hv_wpc_icl = <450>;
		battery,store_mode_buckoff;

		/* trig, recov */
		battery,temp_table_LRP_45W = <385 365>;

		battery,rp_current_rp1 = <500>;
		battery,rp_current_rp2 = <1500>;
		battery,rp_current_rp3 = <3000>;
		battery,rp_current_rdu_rp3 = <2100>;
		battery,rp_current_abnormal_rp3 = <1800>;

		battery,pd_charging_charge_power = <15000>;
		battery,max_charging_current = <2350>;

		battery,store_mode_charging_max = <70>;
		battery,store_mode_charging_min = <60>;

		battery,wireless_cc_cv = <85>;
		battery,wireless_otg_input_current = <900>;

		/* Calculate Based on Offsets from float voltage, full_condition_vcell and recharge_condition_vcell */
		/* if you want to use age_data_by_offset concept add battery,age_data_by_offset; */

		battery,age_data_cycle = <0 300 400 700 1000>;
		battery,age_data_full_condition_soc = <93 92 91 90 89>;
		battery,age_data_chg_float_voltage_offset = <0 20 40 60 110>;
		battery,age_data_full_condition_vcell_offset = <0 20 40 60 110>;
		battery,age_data_recharge_condition_vcell_offset = <0 20 40 60 110>;
		/* battery,age_data_max_charging_current_offset = <0 100 200 300 400>; */

		/* cycle, chg_float_voltage, recharge_condition_vcell, full_condition_vcell, full_condition_soc, step charging condition */
		battery,age_data = <0 4350 4280 4250 93
			300 4330 4260 4230 92
			400 4310 4240 4210 91
			700 4290 4220 4190 90
			1000 4240 4170 4140 89>;


		battery,health_condition_cycle = <900 1200 1500>;
		battery,health_condition_asoc = <0 0 0>; /* Default ASOC Disabled */

		battery,max_input_voltage = <9000>; /* mV */
		battery,max_input_current = <3000>;  /* mA */

		battery,cisd_alg_index = <8>;
		battery,cisd_max_voltage_thr = <4400>; /* batttery ovp dettection voltage */
		battery,ignore_cisd_index = <0 0>;
		battery,ignore_cisd_index_d = <0 80>; /* Do not use BUCK_OFF_PER_DAY, DROP_SENSOR_PER_DAY */

		battery,expired_time = <10800>;
		battery,recharging_expired_time = <5400>;

		battery,battery_full_capacity = <3300>;

		battery,ttf_capacity = <3500>;
		battery,cv_data = <
				3228	864	1534
				3133	866	1524
				3067	872	1493
				3019	874	1483
				2929	879	1452
				2896	881	1442
				2843	883	1431
				2792	885	1421
				2754	887	1411
				2695	892	1380
				2660	893	1370
				2625	895	1360
				2580	897	1349
				2531	898	1339
				2492	902	1319
				2450	903	1309
				2410	905	1298
				2348	908	1278
				2296	909	1268
				2263	910	1257
				2214	915	1227
				2182	916	1216
				2147	919	1196
				2103	920	1186
				2051	922	1175
				2019	924	1155
				1981	927	1134
				1948	928	1124
				1911	930	1104
				1879	932	1093
				1834	933	1083
				1795	935	1063
				1761	938	1032
				1722	942	1001
				1689	944	981
				1649	946	960
				1592	948	940
				1532	950	919
				1493	954	878
				1462	955	868
				1410	958	827
				1362	959	817
				1338	960	807
				1291	964	756
				1264	968	715
				1237	968	704
				1213	969	694
				1169	974	633
				1127	975	622
				1105	975	612
				1073	980	541
				1049	982	510
				1010	983	489
				993	984	479
				972	986	448
				955	988	407
				932	990	387
				881	990	377
				864	996	356
				761	1000	307
				710	1000	297
				688	1000	287
				668	1000	235
				658	1000	215
				647	1000	184
				635	1000	153
				622	1000	123
				610	1000	92
				596	1000	61
				583	1000	31
				571	1000	0
				>;

#if 1
		io-channels = <&auxadc 3>;
		io-channel-names = "adc-chg-temp", "n/a", "n/a", "n/a", "n/a";
#endif
	};

	/* sec_battery_cable
	 *   0	UNKNOWN,
	 *   1	NONE,
	 *   2	PREPARE_TA,
	 *   3	TA,
	 *   4	USB,
	 *   5	USB_CDP,
	 *   6	9V_TA,
	 *   7	9V_ERR,
	 *   8	9V_UNKNOWN,
	 *   9	12V_TA,
	 *  10	WIRELESS,
	 *  11	HV_WIRELESS,
	 *  12	PMA_WIRELESS,
	 *  13	WIRELESS_PACK,
	 *  14	CABLE_WIRELESS_HV_PACK,
	 *  15	WIRELESS_STAND,
	 *  16	WIRELESS_HV_STAND,
	 *  17	QC20,
	 *  18	QC30,
	 *  19	PDIC,
	 *  20	UARTOFF,
	 *  21	OTG,
	 *  22	LAN_HUB,
	 *  23	POWER_SHARING,
	 *  24	HMT_CONNECTED,
	 *  25	HMT_CHARGE,
	 *  26	HV_TA_CHG_LIMIT,
	 *  27	WIRELESS_VEHICLE,
	 *  28	WIRELESS_HV_VEHICLE,
	 *  29	PREPARE_WIRELESS_HV,
	 *  30  TIMEOUT,
	 *  31  SMART_OTG,
	 *  32  SMART_NOTG,
	 *  33  WIRELESS_TX,
	 *  34	HV_WIRELESS_20,
	 *  35	HV_WIRELESS_20_LIMIT,
	 *  36	WIRELESS_FAKE,
	 *  37  PREPARE_WIRELESS_20,
	 *  38	CABLE_PDIC_APDO,
	 *  39  CABLE_POGO,
	 *  40  CABLE_POGO_9V,
	 *  41  FPDO_DC,
	 *  42	CABLE_MAX,
	 */
	sec_battery_cable: cable-info {
		default_input_current = <1800>;
		default_charging_current = <2100>;
		full_check_current_1st = <350>;
		full_check_current_2nd = <200>;

		current_group_1 {
			cable_number = <
				SEC_BATTERY_CABLE_PREPARE_TA
				SEC_BATTERY_CABLE_PDIC
				SEC_BATTERY_CABLE_OTG
				SEC_BATTERY_CABLE_LAN_HUB
				SEC_BATTERY_CABLE_POWER_SHARING>;
			input_current = <500>;
			charging_current = <500>;
		};
		current_group_2 {
			cable_number = <
				SEC_BATTERY_CABLE_HMT_CHARGE
				SEC_BATTERY_CABLE_SMART_OTG>;
			input_current = <1000>;
			charging_current = <1000>;
		};
		current_group_3 {
			cable_number = <
				SEC_BATTERY_CABLE_USB_CDP
				SEC_BATTERY_CABLE_SMART_NOTG>;
			input_current = <1500>;
			charging_current = <1500>;
		};
		current_group_4 {
			cable_number = <SEC_BATTERY_CABLE_9V_TA SEC_BATTERY_CABLE_9V_ERR
				SEC_BATTERY_CABLE_9V_UNKNOWN SEC_BATTERY_CABLE_QC20 SEC_BATTERY_CABLE_QC30>;
			input_current = <1650>;
			charging_current = <2350>;
		};
		current_group_5 {
			cable_number = <SEC_BATTERY_CABLE_12V_TA>;
			input_current = <1650>;
			charging_current = <2350>;
		};
		current_group_6 {
			cable_number = <
				SEC_BATTERY_CABLE_WIRELESS
				SEC_BATTERY_CABLE_PMA_WIRELESS
				SEC_BATTERY_CABLE_WIRELESS_STAND
				SEC_BATTERY_CABLE_WIRELESS_VEHICLE
				SEC_BATTERY_CABLE_WIRELESS_FAKE>;
			input_current = <800>;
			charging_current = <2350>;
		};
		current_group_7 {
			cable_number = <SEC_BATTERY_CABLE_WIRELESS_PACK>;
			input_current = <700>;
			charging_current = <2350>;
		};
		current_group_8 {
			cable_number = <SEC_BATTERY_CABLE_HMT_CONNECTED>;
			input_current = <1000>;
			charging_current = <450>;
		};
		current_group_9 {
			cable_number = <SEC_BATTERY_CABLE_HV_TA_CHG_LIMIT>;
			input_current = <1800>;
			charging_current = <1800>;
		};
		current_group_10 {
			cable_number = <
				SEC_BATTERY_CABLE_HV_WIRELESS
				SEC_BATTERY_CABLE_WIRELESS_HV_PACK
				SEC_BATTERY_CABLE_WIRELESS_HV_STAND
				SEC_BATTERY_CABLE_WIRELESS_HV_VEHICLE
				SEC_BATTERY_CABLE_HV_WIRELESS_20_LIMIT>;
			input_current = <650>;
			charging_current = <2350>;
		};
		current_group_11 {
			cable_number = <
				SEC_BATTERY_CABLE_PREPARE_WIRELESS_HV
				SEC_BATTERY_CABLE_PREPARE_WIRELESS_20>;
			input_current = <500>;
			charging_current = <1200>;
		};
		current_group_12 {
			cable_number = <
				SEC_BATTERY_CABLE_NONE
				SEC_BATTERY_CABLE_USB
				SEC_BATTERY_CABLE_TIMEOUT>;
			input_current = <475>;
			charging_current = <550>;
		};
		current_group_13 {
			cable_number = <SEC_BATTERY_CABLE_HV_WIRELESS_20>;
			input_current = <1200>;
			charging_current = <2350>;
		};
		current_group_14 {
			cable_number = <SEC_BATTERY_CABLE_WIRELESS_TX>;
			input_current = <800>;
			charging_current = <2350>;
		};
	};
	sec_battery_wireless_power_info: wireless-power-info {
		count = <9>;
		current_group_0 {
			wireless_power_class = <2>;
			vout = <9000>;
			input_current_limit = <830>;
			fast_charging_current = <3150>;
			ttf_charge_current = <1500>;
			rx_power = <7500>;
		};
		current_group_1 {
			wireless_power_class = <2>;
			vout = <10000>;
			input_current_limit = <750>;
			fast_charging_current = <3150>;
			ttf_charge_current = <1500>;
			rx_power = <7500>;
		};
		current_group_2 {
			wireless_power_class = <2>;
			vout = <11000>;
			input_current_limit = <680>;
			fast_charging_current = <3150>;
			ttf_charge_current = <1500>;
			rx_power = <7500>;
		};
		current_group_3 {
			wireless_power_class = <2>;
			vout = <12000>;
			input_current_limit = <625>;
			fast_charging_current = <3150>;
			ttf_charge_current = <1500>;
			rx_power = <7500>;
		};
		current_group_4 {
			wireless_power_class = <2>;
			vout = <9000>;
			input_current_limit = <1330>;
			fast_charging_current = <3150>;
			ttf_charge_current = <2175>;
			rx_power = <12000>;
		};
		current_group_5 {
			wireless_power_class = <2>;
			vout = <11000>;
			input_current_limit = <1090>;
			fast_charging_current = <3150>;
			ttf_charge_current = <2100>;
			rx_power = <12000>;
		};
		current_group_6 {
			wireless_power_class = <2>;
			vout = <12000>;
			input_current_limit = <1000>;
			fast_charging_current = <3150>;
			ttf_charge_current = <2100>;
			rx_power = <12000>;
		};
		current_group_7 {
			wireless_power_class = <2>;
			vout = <11000>;
			input_current_limit = <1360>;
			fast_charging_current = <3150>;
			ttf_charge_current = <2300>;
			rx_power = <15000>;
		};
		current_group_8 {
			wireless_power_class = <2>;
			vout = <12000>;
			input_current_limit = <1250>;
			fast_charging_current = <3150>;
			ttf_charge_current = <2300>;
			rx_power = <15000>;
		};
	};
};

/* /home/dpi/qb5_8814/workspace/P4_1716/android/kernel/kmodule/battery/suwon/common/dts/m53x/battery_common.dtsi */
&sec_battery {
		pinctrl-names = "default";

		battery,chip_vendor = "MTK";

		battery,adc_read_type = <SEC_BATTERY_ADC_RAW>;
		battery,temp_check_type = <SEC_BATTERY_TEMP_CHECK_ADC>;
		battery,chg_temp_check_type = <SEC_BATTERY_TEMP_CHECK_ADC>;
		battery,dchg_temp_check_type = <SEC_BATTERY_TEMP_CHECK_TEMP>;

		battery,thermal_source = <SEC_BATTERY_THERMAL_SOURCE_FG_ADC>;
		battery,chg_thermal_source = <SEC_BATTERY_THERMAL_SOURCE_ADC>;
		battery,dchg_thermal_source = <SEC_BATTERY_THERMAL_SOURCE_ADC>;
		battery,dctp_by_cgtp;

		battery,temp_table_adc = <
					200 233 272 318 376 445 521 606 694 811
					946 1103 1282 1436 1592 1750 1906 2030 2142 2290
					2393 2483 2563
					>;
		battery,temp_table_data = <
					900 850 800 750 700 650 600 550 500 450
					400 350 300 250 200 150 100 50 0 (-50)
					(-100) (-150) (-200)
					>;

		battery,chg_temp_table_adc = <
					309 368 448 527 628 746 878 1028 1212 1403
					1622 1899 2211 2482 2755 3035 3312 3570 3776 3998
					4119 4119 4119
					>;
		battery,chg_temp_table_data = <
					900 850 800 750 700 650 600 550 500 450
					400 350 300 250 200 150 100 50 0 (-50)
					(-100) (-150) (-200)
					>;

		battery,temp_check_count = <1>;
		battery,wire_warm_overheat_thresh = <500>;
		battery,wire_normal_warm_thresh = <420>;
		battery,wire_cool1_normal_thresh = <180>;
		battery,wire_cool2_cool1_thresh = <150>;
		battery,wire_cool3_cool2_thresh = <50>;
		battery,wire_cold_cool3_thresh = <0>;

		battery,wire_warm_current = <1700>;	/* 0.36C */
		battery,wire_cool1_current = <2700>; /* 0.72C */
		battery,wire_cool2_current = <1100>;	/* 0.24C */
		battery,wire_cool3_current = <400>;	/* 0.1C */

		battery,high_temp_topoff = <250>;
		battery,low_temp_topoff = <250>;
		battery,high_temp_float = <4200>;
		battery,low_temp_float = <4420>;

		battery,chg_high_temp = <520>;
		battery,chg_high_temp_recovery = <500>;
		battery,chg_input_limit_current = <1000>;
		battery,chg_charging_limit_current = <1900>;

		battery,dchg_high_temp = <520>;
		battery,dchg_high_temp_recovery = <500>;

		battery,full_check_type = <SEC_BATTERY_FULLCHARGED_FG_CURRENT>;
		battery,full_check_type_2nd = <SEC_BATTERY_FULLCHARGED_FG_CURRENT>;

		battery,full_condition_vcell = <4370>;
		battery,recharge_condition_vcell = <4350>;
		battery,chg_float_voltage = <4420>;

		battery,swelling_high_rechg_voltage = <4050>;
		battery,swelling_low_rechg_voltage = <4270>;

		battery,max_charging_current = <2700>;
		battery,max_charging_charge_power = <25000>; /* 25W */

		/* cycle, chg_float_voltage, recharge_condition_vcell, full_condition_vcell, full_condition_soc, step charging condition */
		battery,age_data = <0 4420 4350 4370 93
			300 4400 4330 4350 92
			400 4380 4310 4330 91
			700 4360 4290 4310 90
			1000 4310 4240 4260 89>;

		/* direct step charging option */
		battery,dc_step_chg_type = <0xE9>;
		battery,dc_step_chg_charge_power = <22000>;
		battery,dc_step_chg_step = <3>;
		battery,dc_step_chg_cond_v_margin = <80>; /* mV */
		battery,dc_step_chg_cond_vol = <4110 4250 4420>; /* STEP_CHARGING_CONDITION_VOLTAGE */
		battery,dc_step_chg_cond_iin = <1950 1845 0>; /* STEP_CHARGING_CONDITION_INPUT_CURRENT */
		battery,dc_step_chg_iin_check_cnt = <3>;
		battery,dc_step_chg_cond_soc = <45 60 100>; /* STEP_CHARGING_CONDITION_SOC */
		battery,dc_step_chg_val_vfloat = <4110 4250 4420>; /* STEP_CHARGING_CONDITION_FLOAT_VOLTAGE */
		battery,dc_step_chg_val_iout = <4900 3900 3690>;

		battery,siop_scenarios = <20 0>;
		battery,siop_curr_type_num = <3>;
		/* nv, hv, fpdo */
		battery,siop_icl_20 = <1000 1000 1000>; /* 5W SIOP_DEFAULT 5W */
		battery,siop_fcc_20 = <SIOP_DEFAULT SIOP_DEFAULT SIOP_DEFAULT>;
		battery,siop_icl_0 = <1000 1000 1000>; /* 5W SIOP_DEFAULT 5W */
		battery,siop_fcc_0 = <SIOP_DEFAULT SIOP_DEFAULT SIOP_DEFAULT>;

		battery,standard_curr = <3690>;
		battery,expired_time = <10200>; /* 110 + 60 minutes */
		battery,recharging_expired_time = <5400>;
		battery,battery_full_capacity = <5000>;
		battery,cisd_max_voltage_thr = <5000>; /* batttery ovp dettection voltage */

		battery,inbat_ocv_type =  <SEC_BATTERY_OCV_VOLT_FROM_PMIC>;
		battery,slowcharging_usb_bootcomplete;
		battery,dynamic_cv_factor;

		battery,ttf_hv_charge_current = <2610>;
		battery,ttf_dc25_charge_current = <3800>;
		battery,ttf_capacity = <4555>;
		battery,cv_data = <
					3696	790	1800
					3563	810	1740
					3312	820	1680
					3116	830	1620
					2998	840	1560
					2812	850	1500
					2636	860	1440
					2457	870	1380
					2322	875	1320
					1968	880	1260
					2040	895	1200
					1719	900	1140
					1702	905	1080
					1595	910	1020
					2013	920	960
					1876	925	900
					1772	930	840
					1684	935	780
					1605	940	720
					1520	945	660
					1412	950	600
					1319	955	540
					1231	960	480
					1148	965	420
					1072	970	360
					1005	975	300
					944	980	240
					885	985	180
					825	990	120
					771	995	60
					732	1000	0
					>;
};

&sec_battery_cable {
		full_check_current_1st = <750>;
		full_check_current_2nd = <250>;

		current_group_4 {
			charging_current = <2700>;
		};
		current_group_5 {
			charging_current = <2700>;
		};
		current_group_6 {
			charging_current = <2700>;
		};
		current_group_7 {
			charging_current = <2700>;
		};
		current_group_10 {
			charging_current = <2700>;
		};
};

/* revision devicetree for general */
#include "mt6877.m53x_eur_open.04.dtsi"

/ {
	compatible = "Samsung,M53x EUR OPEN 04","Mediatek,MT6877";
	dtbo-hw_rev = <4>;
	dtbo-hw_rev_end = <32>;
};
